VERSION "dbc-export 1 2025.20.8"

NS_ :

BS_:

BU_: ADSP APB APP APS APSB BB BMS CC CMP CMPD CP DAS DI DIF DIR DPB EPAS3P EPAS3S EPASTP EPASTS EPBL EPBR ESP EVSE FC GTW HCML HCMR HVP IBST ICR IDB LS OCS1P ODIN PARK PCS PLG PM PMF PMR PNCD PTC RADC RCM RCM2 RCM3 RCU SCCM SCM SCS SDCR TAS TCU TPMS TRCM UDS UI UIS UMC USM VC VCFRONT VCLEFT VCRIGHT VCSEC VEH

BO_ 809 APP_warningMatrix0: 8 APP
 SG_ APP_w001_DEPRECATED : 0|1@1+ (1,0) [0|1] "" Vector__XXX
 SG_ APP_w002_ldwDisabled : 1|1@1+ (1,0) [0|1] "" Vector__XXX
 SG_ APP_w003_isaDisabled : 2|1@1+ (1,0) [0|1] "" Vector__XXX
 SG_ APP_w004_accDisabled : 3|1@1+ (1,0) [0|1] "" Vector__XXX
 SG_ APP_w005_fcwCancelled : 4|1@1+ (1,0) [0|1] "" Vector__XXX
 SG_ APP_w006_aebCancelled : 5|1@1+ (1,0) [0|1] "" Vector__XXX
 SG_ APP_w007_ahlbDisabled : 6|1@1+ (1,0) [0|1] "" Vector__XXX
 SG_ APP_w008_parkDisabled : 7|1@1+ (1,0) [0|1] "" Vector__XXX
 SG_ APP_w009_aebFault : 8|1@1+ (1,0) [0|1] "" Vector__XXX
 SG_ APP_w010_radcCalibIssue : 9|1@1+ (1,0) [0|1] "" Vector__XXX
 SG_ APP_w011_scaEvent : 10|1@1+ (1,0) [0|1] "" Vector__XXX
 SG_ APP_w012_Cam_BootFailure : 11|1@1+ (1,0) [0|1] "" Vector__XXX
 SG_ APP_w013_Cam_Watchdog : 12|1@1+ (1,0) [0|1] "" Vector__XXX
 SG_ APP_w014_swAssert : 13|1@1+ (1,0) [0|1] "" Vector__XXX
 SG_ APP_w015_Camera_Failsafes : 14|1@1+ (1,0) [0|1] "" Vector__XXX
 SG_ APP_w016_aeb_e_event : 15|1@1+ (1,0) [0|1] "" Vector__XXX
 SG_ APP_w017_Cam_Msg_MIA : 16|1@1+ (1,0) [0|1] "" Vector__XXX
 SG_ APP_w018_ECU_Power_Issue : 17|1@1+ (1,0) [0|1] "" Vector__XXX
 SG_ APP_w019_ECU_Stack_Overflow : 18|1@1+ (1,0) [0|1] "" Vector__XXX
 SG_ APP_w020_ECU_checkstopError : 19|1@1+ (1,0) [0|1] "" Vector__XXX
 SG_ APP_w021_ECU_Temperature_Issue : 20|1@1+ (1,0) [0|1] "" Vector__XXX
 SG_ APP_w022_ECU_EEPROM_Failure : 21|1@1+ (1,0) [0|1] "" Vector__XXX
 SG_ APP_w023_ECU_Cam_Statemismatc : 22|1@1+ (1,0) [0|1] "" Vector__XXX
 SG_ APP_w024_ECU_Watchdog_Reset : 23|1@1+ (1,0) [0|1] "" Vector__XXX
 SG_ APP_w025_LC_Steering_Override : 24|1@1+ (1,0) [0|1] "" Vector__XXX
 SG_ APP_w026_ECU_timingIssue : 25|1@1+ (1,0) [0|1] "" Vector__XXX
 SG_ APP_w027_ECU_Reset_Fault : 26|1@1+ (1,0) [0|1] "" Vector__XXX
 SG_ APP_w028_spi_rx_error : 27|1@1+ (1,0) [0|1] "" Vector__XXX
 SG_ APP_w029_spi_tx_error : 28|1@1+ (1,0) [0|1] "" Vector__XXX
 SG_ APP_w030_Heater_Issue : 29|1@1+ (1,0) [0|1] "" Vector__XXX
 SG_ APP_w031_canRxError : 30|1@1+ (1,0) [0|1] "" Vector__XXX
 SG_ APP_w032_canTxError : 31|1@1+ (1,0) [0|1] "" Vector__XXX
 SG_ APP_w033_gtwMia : 32|1@1+ (1,0) [0|1] "" Vector__XXX
 SG_ APP_w034_sccmMia : 33|1@1+ (1,0) [0|1] "" Vector__XXX
 SG_ APP_w035_espMia : 34|1@1+ (1,0) [0|1] "" Vector__XXX
 SG_ APP_w036_bdyMia : 35|1@1+ (1,0) [0|1] "" Vector__XXX
 SG_ APP_w037_camTacIssue : 36|1@1+ (1,0) [0|1] "" Vector__XXX
 SG_ APP_w038_camFailure : 37|1@1+ (1,0) [0|1] "" Vector__XXX
 SG_ APP_w039_sdm_rcm_Mia : 38|1@1+ (1,0) [0|1] "" Vector__XXX
 SG_ APP_w040_autopilotAngleSaturated : 39|1@1+ (1,0) [0|1] "" Vector__XXX
 SG_ APP_w041_autopilotRateSaturated : 40|1@1+ (1,0) [0|1] "" Vector__XXX
 SG_ APP_w042_autopilotAborting : 41|1@1+ (1,0) [0|1] "" Vector__XXX
 SG_ APP_w043_camLongRunTime : 42|1@1+ (1,0) [0|1] "" Vector__XXX
 SG_ APP_w044_appMobileyeFailure : 43|1@1+ (1,0) [0|1] "" Vector__XXX
 SG_ APP_w045_radMia : 44|1@1+ (1,0) [0|1] "" Vector__XXX
 SG_ APP_w046_eepromRecordAbsent : 45|1@1+ (1,0) [0|1] "" Vector__XXX
 SG_ APP_w047_edrEvent : 46|1@1+ (1,0) [0|1] "" Vector__XXX
 SG_ APP_w048_APP_Features_Disabled : 47|1@1+ (1,0) [0|1] "" Vector__XXX
 SG_ APP_w049_eyeqVersionMismatch : 48|1@1+ (1,0) [0|1] "" Vector__XXX
 SG_ APP_w050_aeb_event : 49|1@1+ (1,0) [0|1] "" Vector__XXX
 SG_ APP_w051_radcEcuIssue : 50|1@1+ (1,0) [0|1] "" Vector__XXX
 SG_ APP_w052_radcSensorIssue : 51|1@1+ (1,0) [0|1] "" Vector__XXX
 SG_ APP_w053_radcCommIssue : 52|1@1+ (1,0) [0|1] "" Vector__XXX
 SG_ APP_w054_camAutofix : 53|1@1+ (1,0) [0|1] "" Vector__XXX
 SG_ APP_w055_radcVersionMismatch : 54|1@1+ (1,0) [0|1] "" Vector__XXX
 SG_ APP_w056_diMia : 55|1@1+ (1,0) [0|1] "" Vector__XXX
 SG_ APP_w057_mcuMia : 56|1@1+ (1,0) [0|1] "" Vector__XXX
 SG_ APP_w058_epbMia : 57|1@1+ (1,0) [0|1] "" Vector__XXX
 SG_ APP_w059_parkMia : 58|1@1+ (1,0) [0|1] "" Vector__XXX
 SG_ APP_w060_fcw_event : 59|1@1+ (1,0) [0|1] "" Vector__XXX
 SG_ APP_w061_airSuspensionMia : 60|1@1+ (1,0) [0|1] "" Vector__XXX
 SG_ APP_w062_radcAlignment : 61|1@1+ (1,0) [0|1] "" Vector__XXX
 SG_ APP_w063_parkVersionMismatch : 62|1@1+ (1,0) [0|1] "" Vector__XXX
 SG_ APP_w064_epasMia : 63|1@1+ (1,0) [0|1] "" Vector__XXX

BO_ 873 APP_warningMatrix1: 8 APP
 SG_ APP_w065_deserializerOvercurrent : 0|1@1+ (1,0) [0|1] "" Vector__XXX
 SG_ APP_w066_deserializerLockLost : 1|1@1+ (1,0) [0|1] "" Vector__XXX
 SG_ APP_w067_steeringAlignment : 2|1@1+ (1,0) [0|1] "" Vector__XXX
 SG_ APP_w068_vlInconsistency : 3|1@1+ (1,0) [0|1] "" Vector__XXX
 SG_ APP_w069_apcSpaceMasked : 4|1@1+ (1,0) [0|1] "" Vector__XXX
 SG_ APP_w070_apcIncompleteCal : 5|1@1+ (1,0) [0|1] "" Vector__XXX
 SG_ APP_w071_selfparkStarted : 6|1@1+ (1,0) [0|1] "" Vector__XXX
 SG_ APP_w072_selfparkComplete : 7|1@1+ (1,0) [0|1] "" Vector__XXX
 SG_ APP_w073_issueEscalatedLDW : 8|1@1+ (1,0) [0|1] "" Vector__XXX
 SG_ APP_w074_inPathStationaryObst : 9|1@1+ (1,0) [0|1] "" Vector__XXX
 SG_ APP_w075_scMia : 10|1@1+ (1,0) [0|1] "" Vector__XXX
 SG_ APP_w076_mobilEyeSetC : 11|1@1+ (1,0) [0|1] "" Vector__XXX
 SG_ APP_w077_pmmActive : 12|1@1+ (1,0) [0|1] "" Vector__XXX
 SG_ APP_w078_pmmActive2 : 13|1@1+ (1,0) [0|1] "" Vector__XXX
 SG_ APP_w079_edrAvailable : 14|1@1+ (1,0) [0|1] "" Vector__XXX
 SG_ APP_w080_accFailedActivation : 15|1@1+ (1,0) [0|1] "" Vector__XXX
 SG_ APP_w081_pmmActiveBraking : 16|1@1+ (1,0) [0|1] "" Vector__XXX
 SG_ APP_w082_inPathFSviolation : 17|1@1+ (1,0) [0|1] "" Vector__XXX
 SG_ APP_w083_inPathRADObject : 18|1@1+ (1,0) [0|1] "" Vector__XXX
 SG_ APP_w084_pmmIPSO : 19|1@1+ (1,0) [0|1] "" Vector__XXX
 SG_ APP_w085_pmmSteering : 20|1@1+ (1,0) [0|1] "" Vector__XXX
 SG_ APP_w086_robCollision : 21|1@1+ (1,0) [0|1] "" Vector__XXX
 SG_ APP_w087_DEPRECATED : 22|1@1+ (1,0) [0|1] "" Vector__XXX
 SG_ APP_w088_DEPRECATED : 23|1@1+ (1,0) [0|1] "" Vector__XXX
 SG_ APP_w089_DEPRECATED : 24|1@1+ (1,0) [0|1] "" Vector__XXX
 SG_ APP_w090_DEPRECATED : 25|1@1+ (1,0) [0|1] "" Vector__XXX
 SG_ APP_w091_DEPRECATED : 26|1@1+ (1,0) [0|1] "" Vector__XXX
 SG_ APP_w092_DEPRECATED : 27|1@1+ (1,0) [0|1] "" Vector__XXX
 SG_ APP_w093_DEPRECATED : 28|1@1+ (1,0) [0|1] "" Vector__XXX
 SG_ APP_w094_DEPRECATED : 29|1@1+ (1,0) [0|1] "" Vector__XXX
 SG_ APP_w095_DEPRECATED : 30|1@1+ (1,0) [0|1] "" Vector__XXX
 SG_ APP_w096_DEPRECATED : 31|1@1+ (1,0) [0|1] "" Vector__XXX
 SG_ APP_w097_DEPRECATED : 32|1@1+ (1,0) [0|1] "" Vector__XXX
 SG_ APP_w098_DEPRECATED : 33|1@1+ (1,0) [0|1] "" Vector__XXX
 SG_ APP_w099_DEPRECATED : 34|1@1+ (1,0) [0|1] "" Vector__XXX
 SG_ APP_w100_DEPRECATED : 35|1@1+ (1,0) [0|1] "" Vector__XXX
 SG_ APP_w101_DEPRECATED : 36|1@1+ (1,0) [0|1] "" Vector__XXX
 SG_ APP_w102_DEPRECATED : 37|1@1+ (1,0) [0|1] "" Vector__XXX
 SG_ APP_w103_robExperimentalAEB : 38|1@1+ (1,0) [0|1] "" Vector__XXX
 SG_ APP_w104_DEPRECATED : 39|1@1+ (1,0) [0|1] "" Vector__XXX
 SG_ APP_w105_DEPRECATED : 40|1@1+ (1,0) [0|1] "" Vector__XXX
 SG_ APP_w106_torsionBarOffset : 41|1@1+ (1,0) [0|1] "" Vector__XXX

BO_ 1065 APP_warningMatrix2: 8 APP
 SG_ APP_w129_mainCamExtNotCal : 0|1@1+ (1,0) [0|1] "" Vector__XXX
 SG_ APP_w130_narrowCamExtNotCal : 1|1@1+ (1,0) [0|1] "" Vector__XXX
 SG_ APP_w131_mainCamCalSaved : 2|1@1+ (1,0) [0|1] "" Vector__XXX
 SG_ APP_w132_narrowCamCalSaved : 3|1@1+ (1,0) [0|1] "" Vector__XXX
 SG_ APP_w133_mainCamInitFault : 4|1@1+ (1,0) [0|1] "" Vector__XXX
 SG_ APP_w134_narrowCamInitFault : 5|1@1+ (1,0) [0|1] "" Vector__XXX
 SG_ APP_w135_fisheyeCamInitFault : 6|1@1+ (1,0) [0|1] "" Vector__XXX
 SG_ APP_w136_lPillarCamInitFault : 7|1@1+ (1,0) [0|1] "" Vector__XXX
 SG_ APP_w137_rPillarCamInitFault : 8|1@1+ (1,0) [0|1] "" Vector__XXX
 SG_ APP_w138_lRepeatCamInitFault : 9|1@1+ (1,0) [0|1] "" Vector__XXX
 SG_ APP_w139_rRepeatCamInitFault : 10|1@1+ (1,0) [0|1] "" Vector__XXX
 SG_ APP_w140_backupCamInitFault : 11|1@1+ (1,0) [0|1] "" Vector__XXX
 SG_ APP_w141_ECU_Thermal_Issue : 12|1@1+ (1,0) [0|1] "" Vector__XXX
 SG_ APP_w142_fwdCamPitchProblem : 13|1@1+ (1,0) [0|1] "" Vector__XXX
 SG_ APP_w143_IDF_event : 14|1@1+ (1,0) [0|1] "" Vector__XXX
 SG_ APP_w144_fanctrldError : 15|1@1+ (1,0) [0|1] "" Vector__XXX
 SG_ APP_w145_camSelfCalIssue : 16|1@1+ (1,0) [0|1] "" Vector__XXX
 SG_ APP_w146_telemetryProblem : 17|1@1+ (1,0) [0|1] "" Vector__XXX
 SG_ APP_w147_selfieCamInitFault : 18|1@1+ (1,0) [0|1] "" Vector__XXX
 SG_ APP_w148_overlayActive : 19|1@1+ (1,0) [0|1] "" Vector__XXX
 SG_ APP_w149_diskFull : 20|1@1+ (1,0) [0|1] "" Vector__XXX
 SG_ APP_w150_diMiaPartyBus : 21|1@1+ (1,0) [0|1] "" Vector__XXX
 SG_ APP_w151_epasMiaPartyBus : 22|1@1+ (1,0) [0|1] "" Vector__XXX
 SG_ APP_w152_espMiaPartyBus : 23|1@1+ (1,0) [0|1] "" Vector__XXX
 SG_ APP_w153_rcmMiaPartyBus : 24|1@1+ (1,0) [0|1] "" Vector__XXX
 SG_ APP_w154_vcleftMiaPartyBus : 25|1@1+ (1,0) [0|1] "" Vector__XXX
 SG_ APP_w155_vcrightMiaPartyBus : 26|1@1+ (1,0) [0|1] "" Vector__XXX
 SG_ APP_w156_epblMiaVehBus : 27|1@1+ (1,0) [0|1] "" Vector__XXX
 SG_ APP_w157_sccmMiaVehBus : 28|1@1+ (1,0) [0|1] "" Vector__XXX
 SG_ APP_w158_vcfrontMiaVehBus : 29|1@1+ (1,0) [0|1] "" Vector__XXX
 SG_ APP_w159_vcleftMiaVehBus : 30|1@1+ (1,0) [0|1] "" Vector__XXX
 SG_ APP_w160_vcrightMiaVehBus : 31|1@1+ (1,0) [0|1] "" Vector__XXX
 SG_ APP_w161_backupCameraUnavailable : 32|1@1+ (1,0) [0|1] "" Vector__XXX
 SG_ APP_w162_mainCameraTypeError : 33|1@1+ (1,0) [0|1] "" Vector__XXX
 SG_ APP_w163_narrowCameraTypeError : 34|1@1+ (1,0) [0|1] "" Vector__XXX
 SG_ APP_w164_fisheyeCameraTypeError : 35|1@1+ (1,0) [0|1] "" Vector__XXX
 SG_ APP_w165_lPillarCameraTypeError : 36|1@1+ (1,0) [0|1] "" Vector__XXX
 SG_ APP_w166_rPillarCameraTypeError : 37|1@1+ (1,0) [0|1] "" Vector__XXX
 SG_ APP_w167_lRepeatCameraTypeError : 38|1@1+ (1,0) [0|1] "" Vector__XXX
 SG_ APP_w168_rRepeatCameraTypeError : 39|1@1+ (1,0) [0|1] "" Vector__XXX
 SG_ APP_w169_backupCameraTypeError : 40|1@1+ (1,0) [0|1] "" Vector__XXX
 SG_ APP_w170_selfieCameraTypeError : 41|1@1+ (1,0) [0|1] "" Vector__XXX
 SG_ APP_w171_appHighCoolantFlowReq : 42|1@1+ (1,0) [0|1] "" Vector__XXX
 SG_ APP_w172_fisheyeCamExtNotCal : 43|1@1+ (1,0) [0|1] "" Vector__XXX
 SG_ APP_w173_lPillarCamExtNotCal : 44|1@1+ (1,0) [0|1] "" Vector__XXX
 SG_ APP_w174_rPillarCamExtNotCal : 45|1@1+ (1,0) [0|1] "" Vector__XXX
 SG_ APP_w175_lRepeatCamExtNotCal : 46|1@1+ (1,0) [0|1] "" Vector__XXX
 SG_ APP_w176_rRepeatCamExtNotCal : 47|1@1+ (1,0) [0|1] "" Vector__XXX
 SG_ APP_w177_fisheyeCamCalSaved : 48|1@1+ (1,0) [0|1] "" Vector__XXX
 SG_ APP_w178_lPillarCamCalSaved : 49|1@1+ (1,0) [0|1] "" Vector__XXX
 SG_ APP_w179_rPillarCamCalSaved : 50|1@1+ (1,0) [0|1] "" Vector__XXX
 SG_ APP_w180_lRepeatCamCalSaved : 51|1@1+ (1,0) [0|1] "" Vector__XXX
 SG_ APP_w181_rRepeatCamCalSaved : 52|1@1+ (1,0) [0|1] "" Vector__XXX
 SG_ APP_w182_mainCameraStreamExit : 53|1@1+ (1,0) [0|1] "" Vector__XXX
 SG_ APP_w183_narrowCameraStreamExit : 54|1@1+ (1,0) [0|1] "" Vector__XXX
 SG_ APP_w184_fisheyeCameraStreamExit : 55|1@1+ (1,0) [0|1] "" Vector__XXX
 SG_ APP_w185_lPillarCameraStreamExit : 56|1@1+ (1,0) [0|1] "" Vector__XXX
 SG_ APP_w186_rPillarCameraStreamExit : 57|1@1+ (1,0) [0|1] "" Vector__XXX
 SG_ APP_w187_lRepeatCameraStreamExit : 58|1@1+ (1,0) [0|1] "" Vector__XXX
 SG_ APP_w188_rRepeatCameraStreamExit : 59|1@1+ (1,0) [0|1] "" Vector__XXX
 SG_ APP_w189_backupCameraStreamExit : 60|1@1+ (1,0) [0|1] "" Vector__XXX
 SG_ APP_w190_selfieCameraStreamExit : 61|1@1+ (1,0) [0|1] "" Vector__XXX
 SG_ APP_w191_autopilotAborting : 62|1@1+ (1,0) [0|1] "" Vector__XXX
 SG_ APP_w192_emergencySpeakerFail : 63|1@1+ (1,0) [0|1] "" Vector__XXX

BO_ 1081 APP_warningMatrix3: 8 APP
 SG_ APP_w193_camWindshieldUnclean : 0|1@1+ (1,0) [0|1] "" Vector__XXX
 SG_ APP_w194_accDriverResumeRqrd : 1|1@1+ (1,0) [0|1] "" Vector__XXX
 SG_ APP_w195_scwUnavailable : 2|1@1+ (1,0) [0|1] "" Vector__XXX
 SG_ APP_w196_stopSignWarning : 3|1@1+ (1,0) [0|1] "" Vector__XXX
 SG_ APP_w197_redLightWarning : 4|1@1+ (1,0) [0|1] "" Vector__XXX
 SG_ APP_w198_tsrUnavailable : 5|1@1+ (1,0) [0|1] "" Vector__XXX
 SG_ APP_w199_apcAbort : 6|1@1+ (1,0) [0|1] "" Vector__XXX
 SG_ APP_w200_lcSlowdown : 7|1@1+ (1,0) [0|1] "" Vector__XXX
 SG_ APP_w201_lcAborting : 8|1@1+ (1,0) [0|1] "" Vector__XXX
 SG_ APP_w202_scwNoisyEnvironment : 9|1@1+ (1,0) [0|1] "" Vector__XXX
 SG_ APP_w203_apcActivation : 10|1@1+ (1,0) [0|1] "" Vector__XXX
 SG_ APP_w204_apcFinalFront : 11|1@1+ (1,0) [0|1] "" Vector__XXX
 SG_ APP_w205_apcFinalRear : 12|1@1+ (1,0) [0|1] "" Vector__XXX
 SG_ APP_w206_autosteerNotEnabled : 13|1@1+ (1,0) [0|1] "" Vector__XXX
 SG_ APP_w207_autosteerUnavailable : 14|1@1+ (1,0) [0|1] "" Vector__XXX
 SG_ APP_w208_rackDetected : 15|1@1+ (1,0) [0|1] "" Vector__XXX
 SG_ APP_w209_autoSummonRequest : 16|1@1+ (1,0) [0|1] "" Vector__XXX
 SG_ APP_w210_camObstrcted : 17|1@1+ (1,0) [0|1] "" Vector__XXX
 SG_ APP_w211_accNoSeatBelt : 18|1@1+ (1,0) [0|1] "" Vector__XXX
 SG_ APP_w212_lcUnavailableStrikeOut : 19|1@1+ (1,0) [0|1] "" Vector__XXX
 SG_ APP_w213_autosteerStruckOut : 20|1@1+ (1,0) [0|1] "" Vector__XXX
 SG_ APP_w214_driverNotIntracting : 21|1@1+ (1,0) [0|1] "" Vector__XXX
 SG_ APP_w215_contDriverNotIntracting : 22|1@1+ (1,0) [0|1] "" Vector__XXX
 SG_ APP_w216_driverOverriding : 23|1@1+ (1,0) [0|1] "" Vector__XXX
 SG_ APP_w217_lcUnavailableSpeeding : 24|1@1+ (1,0) [0|1] "" Vector__XXX
 SG_ APP_w218_lcSpeedExceededLimit : 25|1@1+ (1,0) [0|1] "" Vector__XXX
 SG_ APP_w219_lcTempUnavailableSpeed : 26|1@1+ (1,0) [0|1] "" Vector__XXX
 SG_ APP_w220_lcTempUnavailableRoad : 27|1@1+ (1,0) [0|1] "" Vector__XXX
 SG_ APP_w221_accRadarBlind : 28|1@1+ (1,0) [0|1] "" Vector__XXX
 SG_ APP_w222_accCameraBlind : 29|1@1+ (1,0) [0|1] "" Vector__XXX
 SG_ APP_w223_accObjectInPath : 30|1@1+ (1,0) [0|1] "" Vector__XXX
 SG_ APP_w224_accCameraCalibration : 31|1@1+ (1,0) [0|1] "" Vector__XXX
 SG_ APP_w225_lcDegradedVisSpeedLmt : 32|1@1+ (1,0) [0|1] "" Vector__XXX
 SG_ APP_w226_lcCamCalNeededSpeedLmt : 33|1@1+ (1,0) [0|1] "" Vector__XXX
 SG_ APP_w227_virtualWallBlocked : 34|1@1+ (1,0) [0|1] "" Vector__XXX
 SG_ APP_w228_DEPRECATED : 35|1@1+ (1,0) [0|1] "" Vector__XXX
 SG_ APP_w229_alcUltrasoundDamaged : 36|1@1+ (1,0) [0|1] "" Vector__XXX
 SG_ APP_w230_alcUltrasoundBlocked : 37|1@1+ (1,0) [0|1] "" Vector__XXX
 SG_ APP_w231_idfEvent : 38|1@1+ (1,0) [0|1] "" Vector__XXX
 SG_ APP_w232_laneChangeRequested : 39|1@1+ (1,0) [0|1] "" Vector__XXX
 SG_ APP_w234_activeSafetyTelemetry : 41|1@1+ (1,0) [0|1] "" Vector__XXX

BO_ 1097 APP_warningMatrix4: 8 APP
 SG_ APP_w257_brakeJerkEvent : 0|1@1+ (1,0) [0|1] "" Vector__XXX
 SG_ APP_w258_aebEvent : 1|1@1+ (1,0) [0|1] "" Vector__XXX
 SG_ APP_w259_aebOverrideEvent : 2|1@1+ (1,0) [0|1] "" Vector__XXX
 SG_ APP_w260_collisionWarningEvent : 3|1@1+ (1,0) [0|1] "" Vector__XXX
 SG_ APP_w261_pcieHardwareErrors : 4|1@1+ (1,0) [0|1] "" Vector__XXX
 SG_ APP_w262_apeCalibMode : 5|1@1+ (1,0) [0|1] "" Vector__XXX
 SG_ APP_w263_lssAbort : 6|1@1+ (1,0) [0|1] "" Vector__XXX
 SG_ APP_w264_lssFault : 7|1@1+ (1,0) [0|1] "" Vector__XXX
 SG_ APP_w265_drvOnNavUnavailable : 8|1@1+ (1,0) [0|1] "" Vector__XXX
 SG_ APP_w266_visionScheduleFallback : 9|1@1+ (1,0) [0|1] "" Vector__XXX
 SG_ APP_w267_benchtopEcu : 10|1@1+ (1,0) [0|1] "" Vector__XXX
 SG_ APP_w268_backupCamExtNotCal : 11|1@1+ (1,0) [0|1] "" Vector__XXX
 SG_ APP_w269_autopilotLimited : 12|1@1+ (1,0) [0|1] "" Vector__XXX
 SG_ APP_w270_blindspotRestricted : 13|1@1+ (1,0) [0|1] "" Vector__XXX
 SG_ APP_w271_laneChangeAborted : 14|1@1+ (1,0) [0|1] "" Vector__XXX
 SG_ APP_w272_laneChangeUnavailable : 15|1@1+ (1,0) [0|1] "" Vector__XXX
 SG_ APP_w273_lssEvent : 16|1@1+ (1,0) [0|1] "" Vector__XXX
 SG_ APP_w274_mainCameraStreamErr : 17|1@1+ (1,0) [0|1] "" Vector__XXX
 SG_ APP_w275_narrowCameraStreamErr : 18|1@1+ (1,0) [0|1] "" Vector__XXX
 SG_ APP_w276_fisheyeCameraStreamErr : 19|1@1+ (1,0) [0|1] "" Vector__XXX
 SG_ APP_w277_lPillarCameraStreamErr : 20|1@1+ (1,0) [0|1] "" Vector__XXX
 SG_ APP_w278_rPillarCameraStreamErr : 21|1@1+ (1,0) [0|1] "" Vector__XXX
 SG_ APP_w279_lRepeatCameraStreamErr : 22|1@1+ (1,0) [0|1] "" Vector__XXX
 SG_ APP_w280_rRepeatCameraStreamErr : 23|1@1+ (1,0) [0|1] "" Vector__XXX
 SG_ APP_w281_backupCameraStreamErr : 24|1@1+ (1,0) [0|1] "" Vector__XXX
 SG_ APP_w282_selfieCameraStreamErr : 25|1@1+ (1,0) [0|1] "" Vector__XXX
 SG_ APP_w283_enhancedSummonAbort : 26|1@1+ (1,0) [0|1] "" Vector__XXX
 SG_ APP_w284_gpsAntennaDisconnected : 27|1@1+ (1,0) [0|1] "" Vector__XXX
 SG_ APP_w285_gpsFaultReset : 28|1@1+ (1,0) [0|1] "" Vector__XXX
 SG_ APP_w286_gpsComIssue : 29|1@1+ (1,0) [0|1] "" Vector__XXX
 SG_ APP_w287_gpsFusionStatus : 30|1@1+ (1,0) [0|1] "" Vector__XXX
 SG_ APP_w288_trafficLightWarning : 31|1@1+ (1,0) [0|1] "" Vector__XXX
 SG_ APP_w289_dramCorrEccErrors : 32|1@1+ (1,0) [0|1] "" Vector__XXX
 SG_ APP_w290_dramUncorrEccErrors : 33|1@1+ (1,0) [0|1] "" Vector__XXX
 SG_ APP_w291_stopSignWarning : 34|1@1+ (1,0) [0|1] "" Vector__XXX
 SG_ APP_w293_mainCameraSyncFailed : 36|1@1+ (1,0) [0|1] "" Vector__XXX
 SG_ APP_w294_narrowCameraSyncFailed : 37|1@1+ (1,0) [0|1] "" Vector__XXX
 SG_ APP_w295_fisheyeCameraSyncFailed : 38|1@1+ (1,0) [0|1] "" Vector__XXX
 SG_ APP_w296_lPillarCameraSyncFailed : 39|1@1+ (1,0) [0|1] "" Vector__XXX
 SG_ APP_w297_rPillarCameraSyncFailed : 40|1@1+ (1,0) [0|1] "" Vector__XXX
 SG_ APP_w298_lRepeatCameraSyncFailed : 41|1@1+ (1,0) [0|1] "" Vector__XXX
 SG_ APP_w299_rRepeatCameraSyncFailed : 42|1@1+ (1,0) [0|1] "" Vector__XXX
 SG_ APP_w300_backupCameraSyncFailed : 43|1@1+ (1,0) [0|1] "" Vector__XXX
 SG_ APP_w301_selfieCameraSyncFailed : 44|1@1+ (1,0) [0|1] "" Vector__XXX
 SG_ APP_w302_vcfrontMiaPartyBus : 45|1@1+ (1,0) [0|1] "" Vector__XXX
 SG_ APP_w303_imuIrational : 46|1@1+ (1,0) [0|1] "" Vector__XXX
 SG_ APP_w304_lssCamBlockedStatus : 47|1@1+ (1,0) [0|1] "" Vector__XXX
 SG_ APP_w305_lssCamStreamExit : 48|1@1+ (1,0) [0|1] "" Vector__XXX
 SG_ APP_w306_lssUltrasonicsBlocked : 49|1@1+ (1,0) [0|1] "" Vector__XXX
 SG_ APP_w307_lssTurnSignalFault : 50|1@1+ (1,0) [0|1] "" Vector__XXX
 SG_ APP_w308_iboosterMia : 51|1@1+ (1,0) [0|1] "" Vector__XXX
 SG_ APP_w309_selfieDisabledOnCar : 52|1@1+ (1,0) [0|1] "" Vector__XXX
 SG_ APP_w310_eth0FrameErrors : 53|1@1+ (1,0) [0|1] "" Vector__XXX
 SG_ APP_w311_eth1FrameErrors : 54|1@1+ (1,0) [0|1] "" Vector__XXX
 SG_ APP_w312_mainCamTypeMismatch : 55|1@1+ (1,0) [0|1] "" Vector__XXX
 SG_ APP_w313_narrowCamTypeMismatch : 56|1@1+ (1,0) [0|1] "" Vector__XXX
 SG_ APP_w314_fisheyeCamTypeMismatch : 57|1@1+ (1,0) [0|1] "" Vector__XXX
 SG_ APP_w315_lPillarCamTypeMismatch : 58|1@1+ (1,0) [0|1] "" Vector__XXX
 SG_ APP_w316_rPillarCamTypeMismatch : 59|1@1+ (1,0) [0|1] "" Vector__XXX
 SG_ APP_w317_lRepeatCamTypeMismatch : 60|1@1+ (1,0) [0|1] "" Vector__XXX
 SG_ APP_w318_rRepeatCamTypeMismatch : 61|1@1+ (1,0) [0|1] "" Vector__XXX
 SG_ APP_w319_backupCamTypeMismatch : 62|1@1+ (1,0) [0|1] "" Vector__XXX
 SG_ APP_w320_selfieCamTypeMismatch : 63|1@1+ (1,0) [0|1] "" Vector__XXX

BO_ 1145 APP_warningMatrix5: 8 APP
 SG_ APP_w321_bmsMia : 0|1@1+ (1,0) [0|1] "" Vector__XXX
 SG_ APP_w322_autoWiperWash : 1|1@1+ (1,0) [0|1] "" Vector__XXX
 SG_ APP_w323_drivableSpaceFCW : 2|1@1+ (1,0) [0|1] "" Vector__XXX
 SG_ APP_w324_adspMia : 3|1@1+ (1,0) [0|1] "" Vector__XXX
 SG_ APP_w325_watchdogReset : 4|1@1+ (1,0) [0|1] "" Vector__XXX
 SG_ APP_w326_kernelPanic : 5|1@1+ (1,0) [0|1] "" Vector__XXX
 SG_ APP_w327_vehicleConfigMismatch : 6|1@1+ (1,0) [0|1] "" Vector__XXX
 SG_ APP_w328_autoparkDegraded : 7|1@1+ (1,0) [0|1] "" Vector__XXX
 SG_ APP_w329_evasiveManeuver : 8|1@1+ (1,0) [0|1] "" Vector__XXX
 SG_ APP_w330_cabinCameraFault : 9|1@1+ (1,0) [0|1] "" Vector__XXX
 SG_ APP_w331_fsdDegradedUnavailable : 10|1@1+ (1,0) [0|1] "" Vector__XXX
 SG_ APP_w332_cameraPositionsSwapped : 11|1@1+ (1,0) [0|1] "" Vector__XXX
 SG_ APP_w333_fsdUnavailableLocation : 12|1@1+ (1,0) [0|1] "" Vector__XXX
 SG_ APP_w334_frontCameraOccluded : 13|1@1+ (1,0) [0|1] "" Vector__XXX
 SG_ APP_w335_tradfcRfSensorError : 14|1@1+ (1,0) [0|1] "" Vector__XXX
 SG_ APP_w336_tradfcLfPmicError : 15|1@1+ (1,0) [0|1] "" Vector__XXX
 SG_ APP_w337_tradfcRfPmicError : 16|1@1+ (1,0) [0|1] "" Vector__XXX
 SG_ APP_w338_tradfcLfTempError : 17|1@1+ (1,0) [0|1] "" Vector__XXX
 SG_ APP_w339_tradfcRfTempError : 18|1@1+ (1,0) [0|1] "" Vector__XXX
 SG_ APP_w340_tradfcCsiError : 19|1@1+ (1,0) [0|1] "" Vector__XXX
 SG_ APP_w341_tradfcCalibError : 20|1@1+ (1,0) [0|1] "" Vector__XXX
 SG_ APP_w342_tradfcDspHwError : 21|1@1+ (1,0) [0|1] "" Vector__XXX
 SG_ APP_w343_tradfcDspSwError : 22|1@1+ (1,0) [0|1] "" Vector__XXX
 SG_ APP_w344_tradfcDspAlgoTimeout : 23|1@1+ (1,0) [0|1] "" Vector__XXX
 SG_ APP_w345_tradfcPerfDegraded : 24|1@1+ (1,0) [0|1] "" Vector__XXX
 SG_ APP_w346_gpsSwEvent : 25|1@1+ (1,0) [0|1] "" Vector__XXX
 SG_ APP_w347_vcbattMiaVehBus : 26|1@1+ (1,0) [0|1] "" Vector__XXX
 SG_ APP_w348_cameraSwUpdateRequired : 27|1@1+ (1,0) [0|1] "" Vector__XXX
 SG_ APP_w349_cameraPersistentlyFault : 28|1@1+ (1,0) [0|1] "" Vector__XXX
 SG_ APP_w350_tradfcSensorMisaligned : 29|1@1+ (1,0) [0|1] "" Vector__XXX
 SG_ APP_w351_csiDevice0Down : 30|1@1+ (1,0) [0|1] "" Vector__XXX
 SG_ APP_w352_csiDevice1Down : 31|1@1+ (1,0) [0|1] "" Vector__XXX
 SG_ APP_w353_csiDevice2Down : 32|1@1+ (1,0) [0|1] "" Vector__XXX
 SG_ APP_w354_tradfcMia : 33|1@1+ (1,0) [0|1] "" Vector__XXX
 SG_ APP_w355_camQuadPowerFault : 34|1@1+ (1,0) [0|1] "" Vector__XXX
 SG_ APP_w356_driverOverriding : 35|1@1+ (1,0) [0|1] "" Vector__XXX
 SG_ APP_w357_ddawSystemFault : 36|1@1+ (1,0) [0|1] "" Vector__XXX
 SG_ APP_w358_isaSystemFault : 37|1@1+ (1,0) [0|1] "" Vector__XXX
 SG_ APP_w359_aebDegraded : 38|1@1+ (1,0) [0|1] "" Vector__XXX
 SG_ APP_w360_ApImuNoiseDetected : 39|1@1+ (1,0) [0|1] "" Vector__XXX
 SG_ APP_w361_cabinCameraLEDFault : 40|1@1+ (1,0) [0|1] "" Vector__XXX
 SG_ APP_w362_fasciaCamInitFault : 41|1@1+ (1,0) [0|1] "" Vector__XXX
 SG_ APP_w363_fasciaCameraStreamExit : 42|1@1+ (1,0) [0|1] "" Vector__XXX
 SG_ APP_w364_fasciaCameraTypeError : 43|1@1+ (1,0) [0|1] "" Vector__XXX
 SG_ APP_w365_fasciaCamExtNotCal : 44|1@1+ (1,0) [0|1] "" Vector__XXX
 SG_ APP_w366_fasciaCameraSyncFailed : 45|1@1+ (1,0) [0|1] "" Vector__XXX
 SG_ APP_w367_fasciaCamCalSaved : 46|1@1+ (1,0) [0|1] "" Vector__XXX
 SG_ APP_w368_fasciaCamTypeMismatch : 47|1@1+ (1,0) [0|1] "" Vector__XXX
 SG_ APP_w369_cruiseWithSingleClick : 48|1@1+ (1,0) [0|1] "" Vector__XXX
 SG_ APP_w370_accApUnavUserSettings : 49|1@1+ (1,0) [0|1] "" Vector__XXX
 SG_ APP_w371_networkLoadingIssue : 50|1@1+ (1,0) [0|1] "" Vector__XXX
 SG_ APP_w372_cabinCameraBlocked : 51|1@1+ (1,0) [0|1] "" Vector__XXX
 SG_ APP_w373_gnssUartError : 52|1@1+ (1,0) [0|1] "" Vector__XXX
 SG_ APP_w374_gnssUartDataMia : 53|1@1+ (1,0) [0|1] "" Vector__XXX
 SG_ APP_w375_gnssPpsMia : 54|1@1+ (1,0) [0|1] "" Vector__XXX
 SG_ APP_w376_wheeltickCountMia : 55|1@1+ (1,0) [0|1] "" Vector__XXX
 SG_ APP_w377_apImuMia : 56|1@1+ (1,0) [0|1] "" Vector__XXX
 SG_ APP_w378_ubloxImuMia : 57|1@1+ (1,0) [0|1] "" Vector__XXX
 SG_ APP_w379_positioningEngineMia : 58|1@1+ (1,0) [0|1] "" Vector__XXX
 SG_ APP_w380_gnssPpsTimestampIssue : 59|1@1+ (1,0) [0|1] "" Vector__XXX
 SG_ APP_w381_apImuTimestampIssue : 60|1@1+ (1,0) [0|1] "" Vector__XXX
 SG_ APP_w382_ubloxImuTimestampIssue : 61|1@1+ (1,0) [0|1] "" Vector__XXX
 SG_ APP_w383_manyApRebootsWhileInP : 62|1@1+ (1,0) [0|1] "" Vector__XXX
 SG_ APP_w384_posEngineInitInMotion : 63|1@1+ (1,0) [0|1] "" Vector__XXX

BO_ 1149 APP_warningMatrix6: 8 APP
 SG_ APP_w385_posEngineUnhealthy : 0|1@1+ (1,0) [0|1] "" Vector__XXX
 SG_ APP_w386_radarOnlyBrakingEvent : 1|1@1+ (1,0) [0|1] "" Vector__XXX
 SG_ APP_w387_radarBlockageDetected : 2|1@1+ (1,0) [0|1] "" Vector__XXX
 SG_ APP_w388_windshieldCameraHeaterF : 3|1@1+ (1,0) [0|1] "" Vector__XXX
 SG_ APP_w389_camFovResidueDetected : 4|1@1+ (1,0) [0|1] "" Vector__XXX
 SG_ APP_w390_cabinCamVisDegraded : 5|1@1+ (1,0) [0|1] "" Vector__XXX
 SG_ APP_w391_cabinCameraBlockedonAP : 6|1@1+ (1,0) [0|1] "" Vector__XXX
 SG_ APP_w392_fsdSuspended : 7|1@1+ (1,0) [0|1] "" Vector__XXX
 SG_ APP_w393_attnMntrUnavailable : 8|1@1+ (1,0) [0|1] "" Vector__XXX
 SG_ APP_w394_apImuGrossErrors : 9|1@1+ (1,0) [0|1] "" Vector__XXX
 SG_ APP_w395_cabinCameraLEDFaultSvc : 10|1@1+ (1,0) [0|1] "" Vector__XXX
 SG_ APP_w396_severeResidueDetected : 11|1@1+ (1,0) [0|1] "" Vector__XXX
 SG_ APP_w397_apFeatDisabledPermanent : 12|1@1+ (1,0) [0|1] "" Vector__XXX
 SG_ APP_w398_imuOutputUnhealthy : 13|1@1+ (1,0) [0|1] "" Vector__XXX
 SG_ APP_w399_brakeboosterMia : 14|1@1+ (1,0) [0|1] "" Vector__XXX
 SG_ APP_w400_selfieCameraFanFault : 15|1@1+ (1,0) [0|1] "" Vector__XXX
 SG_ APP_w401_leftPillarCameraHeaterF : 16|1@1+ (1,0) [0|1] "" Vector__XXX
 SG_ APP_w402_rightPillarCameraHeater : 17|1@1+ (1,0) [0|1] "" Vector__XXX

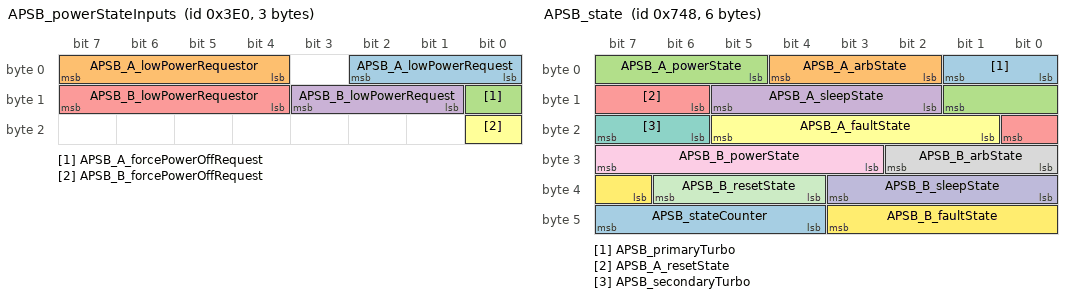
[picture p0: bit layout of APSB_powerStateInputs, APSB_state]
BO_ 992 APSB_powerStateInputs: 3 APSB
 SG_ APSB_A_lowPowerRequest : 0|3@1+ (1,0) [0|7] "" Vector__XXX
 SG_ APSB_A_lowPowerRequestor : 4|4@1+ (1,0) [0|15] "" Vector__XXX
 SG_ APSB_A_forcePowerOffRequest : 8|1@1+ (1,0) [0|1] "" Vector__XXX
 SG_ APSB_B_lowPowerRequest : 9|3@1+ (1,0) [0|7] "" Vector__XXX
 SG_ APSB_B_lowPowerRequestor : 12|4@1+ (1,0) [0|15] "" Vector__XXX
 SG_ APSB_B_forcePowerOffRequest : 16|1@1+ (1,0) [0|1] "" Vector__XXX

BO_ 1864 APSB_state: 6 APSB
 SG_ APSB_primaryTurbo : 0|2@1+ (1,0) [0|3] "" Vector__XXX
 SG_ APSB_A_arbState : 2|3@1+ (1,0) [0|7] "" Vector__XXX
 SG_ APSB_A_powerState : 5|5@1+ (1,0) [0|31] "" Vector__XXX
 SG_ APSB_A_sleepState : 10|4@1+ (1,0) [0|15] "" Vector__XXX
 SG_ APSB_A_resetState : 14|3@1+ (1,0) [0|7] "" Vector__XXX
 SG_ APSB_A_faultState : 17|5@1+ (1,0) [0|31] "" Vector__XXX
 SG_ APSB_secondaryTurbo : 22|2@1+ (1,0) [0|3] "" Vector__XXX
 SG_ APSB_B_arbState : 24|3@1+ (1,0) [0|7] "" Vector__XXX
 SG_ APSB_B_powerState : 27|5@1+ (1,0) [0|31] "" Vector__XXX
 SG_ APSB_B_sleepState : 32|4@1+ (1,0) [0|15] "" Vector__XXX
 SG_ APSB_B_resetState : 36|3@1+ (1,0) [0|7] "" Vector__XXX
 SG_ APSB_B_faultState : 39|5@1+ (1,0) [0|31] "" Vector__XXX
 SG_ APSB_stateCounter : 44|4@1+ (1,0) [0|15] "" Vector__XXX

BO_ 971 APSB_status: 8 APSB
 SG_ APSB_appStatusMonitorState : 0|3@1+ (1,0) [0|7] "" Vector__XXX
 SG_ APSB_vehBehaviorState : 4|4@1+ (1,0) [0|15] "" Vector__XXX
 SG_ APSB_canMaster : 8|2@1+ (1,0) [0|2] "" Vector__XXX
 SG_ APSB_appGpioState : 10|2@1+ (1,0) [0|3] "" Vector__XXX
 SG_ APSB_eacInternalState : 12|3@1+ (1,0) [0|7] "" Vector__XXX
 SG_ APSB_switchState : 15|1@1+ (1,0) [0|1] "" Vector__XXX
 SG_ APSB_apbStatusMonitorState : 16|3@1+ (1,0) [0|7] "" Vector__XXX
 SG_ APSB_apbGpioState : 20|2@1+ (1,0) [0|3] "" Vector__XXX
 SG_ APSB_statusCounter : 22|4@1+ (1,0) [0|15] "" Vector__XXX
 SG_ APSB_locLimitReason : 26|3@1+ (1,0) [0|7] "" Vector__XXX
 SG_ APSB_appPowerStateRequest : 29|2@1+ (1,0) [0|3] "" Vector__XXX
 SG_ APSB_appPowerStateReason : 31|4@1+ (1,0) [0|15] "" Vector__XXX
 SG_ APSB_apbPowerStateRequest : 36|2@1+ (1,0) [0|3] "" Vector__XXX
 SG_ APSB_apbPowerStateReason : 38|4@1+ (1,0) [0|15] "" Vector__XXX
 SG_ APSB_heaterStateDebug : 43|3@1+ (1,0) [0|6] "" Vector__XXX
 SG_ APSB_autosummonCounter : 46|3@1+ (1,0) [0|7] "" Vector__XXX
 SG_ APSB_autosummonAlert : 49|1@1+ (1,0) [0|1] "" Vector__XXX
 SG_ APSB_gpsAntennaState : 50|2@1+ (1,0) [0|3] "" Vector__XXX
 SG_ APSB_arbState : 52|3@1+ (1,0) [0|7] "" Vector__XXX
 SG_ APSB_socPowerOperatingMode : 55|2@1+ (1,0) [0|3] "" Vector__XXX

BO_TX_BU_ 809 : APP;
BO_TX_BU_ 873 : APP;
BO_TX_BU_ 1065 : APP;
BO_TX_BU_ 1081 : APP;
BO_TX_BU_ 1097 : APP;
BO_TX_BU_ 1145 : APP;
BO_TX_BU_ 1149 : APP;
BO_TX_BU_ 992 : APSB;
BO_TX_BU_ 1864 : APSB;
BO_TX_BU_ 971 : APSB;
CM_ BO_ 809 "Driver assistance computer (primary) message: warning matrix0";
CM_ SG_ 809 APP_w001_DEPRECATED "Driver assistance computer (primary): w001 DEPRECATED";
CM_ SG_ 809 APP_w002_ldwDisabled "Driver assistance computer (primary): w002 ldw disabled";
CM_ SG_ 809 APP_w003_isaDisabled "Driver assistance computer (primary): w003 isa disabled";
CM_ SG_ 809 APP_w004_accDisabled "Driver assistance computer (primary): w004 acc disabled";
CM_ SG_ 809 APP_w005_fcwCancelled "Driver assistance computer (primary): w005 fcw cancelled";
CM_ SG_ 809 APP_w006_aebCancelled "Driver assistance computer (primary): w006 aeb cancelled";
CM_ SG_ 809 APP_w007_ahlbDisabled "Driver assistance computer (primary): w007 ahlb disabled";
CM_ SG_ 809 APP_w008_parkDisabled "Driver assistance computer (primary): w008 park disabled";
CM_ SG_ 809 APP_w009_aebFault "Driver assistance computer (primary): w009 aeb fault";
CM_ SG_ 809 APP_w010_radcCalibIssue "Driver assistance computer (primary): w010 radc calib issue";
CM_ SG_ 809 APP_w011_scaEvent "Driver assistance computer (primary): w011 sca event";
CM_ SG_ 809 APP_w012_Cam_BootFailure "Driver assistance computer (primary): w012 cam boot failure";
CM_ SG_ 809 APP_w013_Cam_Watchdog "Driver assistance computer (primary): w013 cam watchdog";
CM_ SG_ 809 APP_w014_swAssert "Driver assistance computer (primary): w014 sw assert";
CM_ SG_ 809 APP_w015_Camera_Failsafes "Driver assistance computer (primary): w015 camera failsafes";
CM_ SG_ 809 APP_w016_aeb_e_event "Driver assistance computer (primary): w016 aeb e event";
CM_ SG_ 809 APP_w017_Cam_Msg_MIA "Driver assistance computer (primary): w017 cam msg MIA";
CM_ SG_ 809 APP_w018_ECU_Power_Issue "Driver assistance computer (primary): w018 ECU power issue";
CM_ SG_ 809 APP_w019_ECU_Stack_Overflow "Driver assistance computer (primary): w019 ECU stack overflow";
CM_ SG_ 809 APP_w020_ECU_checkstopError "Driver assistance computer (primary): w020 ECU checkstop error";
CM_ SG_ 809 APP_w021_ECU_Temperature_Issue "Driver assistance computer (primary): w021 ECU temperature issue";
CM_ SG_ 809 APP_w022_ECU_EEPROM_Failure "Driver assistance computer (primary): w022 ECU EEPROM failure";
CM_ SG_ 809 APP_w023_ECU_Cam_Statemismatc "Driver assistance computer (primary): w023 ECU cam statemismatc";
CM_ SG_ 809 APP_w024_ECU_Watchdog_Reset "Driver assistance computer (primary): w024 ECU watchdog reset";
CM_ SG_ 809 APP_w025_LC_Steering_Override "Driver assistance computer (primary): w025 LC steering override";
CM_ SG_ 809 APP_w026_ECU_timingIssue "Driver assistance computer (primary): w026 ECU timing issue";
CM_ SG_ 809 APP_w027_ECU_Reset_Fault "Driver assistance computer (primary): w027 ECU reset fault";
CM_ SG_ 809 APP_w028_spi_rx_error "Driver assistance computer (primary): w028 spi rx error";
CM_ SG_ 809 APP_w029_spi_tx_error "Driver assistance computer (primary): w029 spi tx error";
CM_ SG_ 809 APP_w030_Heater_Issue "Driver assistance computer (primary): w030 heater issue";
CM_ SG_ 809 APP_w031_canRxError "Driver assistance computer (primary): w031 can rx error";
CM_ SG_ 809 APP_w032_canTxError "Driver assistance computer (primary): w032 can tx error";
CM_ SG_ 809 APP_w033_gtwMia "Driver assistance computer (primary): w033 gtw mia";
CM_ SG_ 809 APP_w034_sccmMia "Driver assistance computer (primary): w034 sccm mia";
CM_ SG_ 809 APP_w035_espMia "Driver assistance computer (primary): w035 esp mia";
CM_ SG_ 809 APP_w036_bdyMia "Driver assistance computer (primary): w036 bdy mia";
CM_ SG_ 809 APP_w037_camTacIssue "Driver assistance computer (primary): w037 cam tac issue";
CM_ SG_ 809 APP_w038_camFailure "Driver assistance computer (primary): w038 cam failure";
CM_ SG_ 809 APP_w039_sdm_rcm_Mia "Driver assistance computer (primary): w039 sdm rcm mia";
CM_ SG_ 809 APP_w040_autopilotAngleSaturated "Driver assistance computer (primary): w040 autopilot angle saturated";
CM_ SG_ 809 APP_w041_autopilotRateSaturated "Driver assistance computer (primary): w041 autopilot rate saturated";
CM_ SG_ 809 APP_w042_autopilotAborting "Driver assistance computer (primary): w042 autopilot aborting";
CM_ SG_ 809 APP_w043_camLongRunTime "Driver assistance computer (primary): w043 cam long run time";
CM_ SG_ 809 APP_w044_appMobileyeFailure "Driver assistance computer (primary): w044 app mobileye failure";
CM_ SG_ 809 APP_w045_radMia "Driver assistance computer (primary): w045 rad mia";
CM_ SG_ 809 APP_w046_eepromRecordAbsent "Driver assistance computer (primary): w046 eeprom record absent";
CM_ SG_ 809 APP_w047_edrEvent "Driver assistance computer (primary): w047 edr event";
CM_ SG_ 809 APP_w048_APP_Features_Disabled "Driver assistance computer (primary): w048 APP features disabled";
CM_ SG_ 809 APP_w049_eyeqVersionMismatch "Driver assistance computer (primary): w049 eyeq version mismatch";
CM_ SG_ 809 APP_w050_aeb_event "Driver assistance computer (primary): w050 aeb event";
CM_ SG_ 809 APP_w051_radcEcuIssue "Driver assistance computer (primary): w051 radc ecu issue";
CM_ SG_ 809 APP_w052_radcSensorIssue "Driver assistance computer (primary): w052 radc sensor issue";
CM_ SG_ 809 APP_w053_radcCommIssue "Driver assistance computer (primary): w053 radc comm issue";
CM_ SG_ 809 APP_w054_camAutofix "Driver assistance computer (primary): w054 cam autofix";
CM_ SG_ 809 APP_w055_radcVersionMismatch "Driver assistance computer (primary): w055 radc version mismatch";
CM_ SG_ 809 APP_w056_diMia "Driver assistance computer (primary): w056 di mia";
CM_ SG_ 809 APP_w057_mcuMia "Driver assistance computer (primary): w057 mcu mia";
CM_ SG_ 809 APP_w058_epbMia "Driver assistance computer (primary): w058 epb mia";
CM_ SG_ 809 APP_w059_parkMia "Driver assistance computer (primary): w059 park mia";
CM_ SG_ 809 APP_w060_fcw_event "Driver assistance computer (primary): w060 fcw event";
CM_ SG_ 809 APP_w061_airSuspensionMia "Driver assistance computer (primary): w061 air suspension mia";
CM_ SG_ 809 APP_w062_radcAlignment "Driver assistance computer (primary): w062 radc alignment";
CM_ SG_ 809 APP_w063_parkVersionMismatch "Driver assistance computer (primary): w063 park version mismatch";
CM_ SG_ 809 APP_w064_epasMia "Driver assistance computer (primary): w064 epas mia";
CM_ BO_ 873 "Driver assistance computer (primary) message: warning matrix1";
CM_ SG_ 873 APP_w065_deserializerOvercurrent "Driver assistance computer (primary): w065 deserializer overcurrent";
CM_ SG_ 873 APP_w066_deserializerLockLost "Driver assistance computer (primary): w066 deserializer lock lost";
CM_ SG_ 873 APP_w067_steeringAlignment "Driver assistance computer (primary): w067 steering alignment";
CM_ SG_ 873 APP_w068_vlInconsistency "Driver assistance computer (primary): w068 vl inconsistency";
CM_ SG_ 873 APP_w069_apcSpaceMasked "Driver assistance computer (primary): w069 apc space masked";
CM_ SG_ 873 APP_w070_apcIncompleteCal "Driver assistance computer (primary): w070 apc incomplete cal";
CM_ SG_ 873 APP_w071_selfparkStarted "Driver assistance computer (primary): w071 selfpark started";
CM_ SG_ 873 APP_w072_selfparkComplete "Driver assistance computer (primary): w072 selfpark complete";
CM_ SG_ 873 APP_w073_issueEscalatedLDW "Driver assistance computer (primary): w073 issue escalated LDW";
CM_ SG_ 873 APP_w074_inPathStationaryObst "Driver assistance computer (primary): w074 in path stationary obst";
CM_ SG_ 873 APP_w075_scMia "Driver assistance computer (primary): w075 sc mia";
CM_ SG_ 873 APP_w076_mobilEyeSetC "Driver assistance computer (primary): w076 mobil eye set c";
CM_ SG_ 873 APP_w077_pmmActive "Driver assistance computer (primary): w077 pmm active";
CM_ SG_ 873 APP_w078_pmmActive2 "Driver assistance computer (primary): w078 pmm active2";
CM_ SG_ 873 APP_w079_edrAvailable "Driver assistance computer (primary): w079 edr available";
CM_ SG_ 873 APP_w080_accFailedActivation "Driver assistance computer (primary): w080 acc failed activation";
CM_ SG_ 873 APP_w081_pmmActiveBraking "Driver assistance computer (primary): w081 pmm active braking";
CM_ SG_ 873 APP_w082_inPathFSviolation "Driver assistance computer (primary): w082 in path f sviolation";
CM_ SG_ 873 APP_w083_inPathRADObject "Driver assistance computer (primary): w083 in path RAD object";
CM_ SG_ 873 APP_w084_pmmIPSO "Driver assistance computer (primary): w084 pmm IPSO";
CM_ SG_ 873 APP_w085_pmmSteering "Driver assistance computer (primary): w085 pmm steering";
CM_ SG_ 873 APP_w086_robCollision "Driver assistance computer (primary): w086 rob collision";
CM_ SG_ 873 APP_w087_DEPRECATED "Driver assistance computer (primary): w087 DEPRECATED";
CM_ SG_ 873 APP_w088_DEPRECATED "Driver assistance computer (primary): w088 DEPRECATED";
CM_ SG_ 873 APP_w089_DEPRECATED "Driver assistance computer (primary): w089 DEPRECATED";
CM_ SG_ 873 APP_w090_DEPRECATED "Driver assistance computer (primary): w090 DEPRECATED";
CM_ SG_ 873 APP_w091_DEPRECATED "Driver assistance computer (primary): w091 DEPRECATED";
CM_ SG_ 873 APP_w092_DEPRECATED "Driver assistance computer (primary): w092 DEPRECATED";
CM_ SG_ 873 APP_w093_DEPRECATED "Driver assistance computer (primary): w093 DEPRECATED";
CM_ SG_ 873 APP_w094_DEPRECATED "Driver assistance computer (primary): w094 DEPRECATED";
CM_ SG_ 873 APP_w095_DEPRECATED "Driver assistance computer (primary): w095 DEPRECATED";
CM_ SG_ 873 APP_w096_DEPRECATED "Driver assistance computer (primary): w096 DEPRECATED";
CM_ SG_ 873 APP_w097_DEPRECATED "Driver assistance computer (primary): w097 DEPRECATED";
CM_ SG_ 873 APP_w098_DEPRECATED "Driver assistance computer (primary): w098 DEPRECATED";
CM_ SG_ 873 APP_w099_DEPRECATED "Driver assistance computer (primary): w099 DEPRECATED";
CM_ SG_ 873 APP_w100_DEPRECATED "Driver assistance computer (primary): w100 DEPRECATED";
CM_ SG_ 873 APP_w101_DEPRECATED "Driver assistance computer (primary): w101 DEPRECATED";
CM_ SG_ 873 APP_w102_DEPRECATED "Driver assistance computer (primary): w102 DEPRECATED";
CM_ SG_ 873 APP_w103_robExperimentalAEB "Driver assistance computer (primary): w103 rob experimental AEB";
CM_ SG_ 873 APP_w104_DEPRECATED "Driver assistance computer (primary): w104 DEPRECATED";
CM_ SG_ 873 APP_w105_DEPRECATED "Driver assistance computer (primary): w105 DEPRECATED";
CM_ SG_ 873 APP_w106_torsionBarOffset "Driver assistance computer (primary): w106 torsion bar offset";
CM_ BO_ 1065 "Driver assistance computer (primary) message: warning matrix2";
CM_ SG_ 1065 APP_w129_mainCamExtNotCal "Driver assistance computer (primary): w129 main cam ext not cal";
CM_ SG_ 1065 APP_w130_narrowCamExtNotCal "Driver assistance computer (primary): w130 narrow cam ext not cal";
CM_ SG_ 1065 APP_w131_mainCamCalSaved "Driver assistance computer (primary): w131 main cam cal saved";
CM_ SG_ 1065 APP_w132_narrowCamCalSaved "Driver assistance computer (primary): w132 narrow cam cal saved";
CM_ SG_ 1065 APP_w133_mainCamInitFault "Driver assistance computer (primary): w133 main cam init fault";
CM_ SG_ 1065 APP_w134_narrowCamInitFault "Driver assistance computer (primary): w134 narrow cam init fault";
CM_ SG_ 1065 APP_w135_fisheyeCamInitFault "Driver assistance computer (primary): w135 fisheye cam init fault";
CM_ SG_ 1065 APP_w136_lPillarCamInitFault "Driver assistance computer (primary): w136 l pillar cam init fault";
CM_ SG_ 1065 APP_w137_rPillarCamInitFault "Driver assistance computer (primary): w137 r pillar cam init fault";
CM_ SG_ 1065 APP_w138_lRepeatCamInitFault "Driver assistance computer (primary): w138 l repeat cam init fault";
CM_ SG_ 1065 APP_w139_rRepeatCamInitFault "Driver assistance computer (primary): w139 r repeat cam init fault";
CM_ SG_ 1065 APP_w140_backupCamInitFault "Driver assistance computer (primary): w140 backup cam init fault";
CM_ SG_ 1065 APP_w141_ECU_Thermal_Issue "Driver assistance computer (primary): w141 ECU thermal issue";
CM_ SG_ 1065 APP_w142_fwdCamPitchProblem "Driver assistance computer (primary): w142 fwd cam pitch problem";
CM_ SG_ 1065 APP_w143_IDF_event "Driver assistance computer (primary): w143 IDF event";
CM_ SG_ 1065 APP_w144_fanctrldError "Driver assistance computer (primary): w144 fanctrld error";
CM_ SG_ 1065 APP_w145_camSelfCalIssue "Driver assistance computer (primary): w145 cam self cal issue";
CM_ SG_ 1065 APP_w146_telemetryProblem "Driver assistance computer (primary): w146 telemetry problem";
CM_ SG_ 1065 APP_w147_selfieCamInitFault "Driver assistance computer (primary): w147 selfie cam init fault";
CM_ SG_ 1065 APP_w148_overlayActive "Driver assistance computer (primary): w148 overlay active";
CM_ SG_ 1065 APP_w149_diskFull "Driver assistance computer (primary): w149 disk full";
CM_ SG_ 1065 APP_w150_diMiaPartyBus "Driver assistance computer (primary): w150 di mia party bus";
CM_ SG_ 1065 APP_w151_epasMiaPartyBus "Driver assistance computer (primary): w151 epas mia party bus";
CM_ SG_ 1065 APP_w152_espMiaPartyBus "Driver assistance computer (primary): w152 esp mia party bus";
CM_ SG_ 1065 APP_w153_rcmMiaPartyBus "Driver assistance computer (primary): w153 rcm mia party bus";
CM_ SG_ 1065 APP_w154_vcleftMiaPartyBus "Driver assistance computer (primary): w154 vcleft mia party bus";
CM_ SG_ 1065 APP_w155_vcrightMiaPartyBus "Driver assistance computer (primary): w155 vcright mia party bus";
CM_ SG_ 1065 APP_w156_epblMiaVehBus "Driver assistance computer (primary): w156 epbl mia veh bus";
CM_ SG_ 1065 APP_w157_sccmMiaVehBus "Driver assistance computer (primary): w157 sccm mia veh bus";
CM_ SG_ 1065 APP_w158_vcfrontMiaVehBus "Driver assistance computer (primary): w158 vcfront mia veh bus";
CM_ SG_ 1065 APP_w159_vcleftMiaVehBus "Driver assistance computer (primary): w159 vcleft mia veh bus";
CM_ SG_ 1065 APP_w160_vcrightMiaVehBus "Driver assistance computer (primary): w160 vcright mia veh bus";
CM_ SG_ 1065 APP_w161_backupCameraUnavailable "Driver assistance computer (primary): w161 backup camera unavailable";
CM_ SG_ 1065 APP_w162_mainCameraTypeError "Driver assistance computer (primary): w162 main camera type error";
CM_ SG_ 1065 APP_w163_narrowCameraTypeError "Driver assistance computer (primary): w163 narrow camera type error";
CM_ SG_ 1065 APP_w164_fisheyeCameraTypeError "Driver assistance computer (primary): w164 fisheye camera type error";
CM_ SG_ 1065 APP_w165_lPillarCameraTypeError "Driver assistance computer (primary): w165 l pillar camera type error";
CM_ SG_ 1065 APP_w166_rPillarCameraTypeError "Driver assistance computer (primary): w166 r pillar camera type error";
CM_ SG_ 1065 APP_w167_lRepeatCameraTypeError "Driver assistance computer (primary): w167 l repeat camera type error";
CM_ SG_ 1065 APP_w168_rRepeatCameraTypeError "Driver assistance computer (primary): w168 r repeat camera type error";
CM_ SG_ 1065 APP_w169_backupCameraTypeError "Driver assistance computer (primary): w169 backup camera type error";
CM_ SG_ 1065 APP_w170_selfieCameraTypeError "Driver assistance computer (primary): w170 selfie camera type error";
CM_ SG_ 1065 APP_w171_appHighCoolantFlowReq "Driver assistance computer (primary): w171 app high coolant flow req";
CM_ SG_ 1065 APP_w172_fisheyeCamExtNotCal "Driver assistance computer (primary): w172 fisheye cam ext not cal";
CM_ SG_ 1065 APP_w173_lPillarCamExtNotCal "Driver assistance computer (primary): w173 l pillar cam ext not cal";
CM_ SG_ 1065 APP_w174_rPillarCamExtNotCal "Driver assistance computer (primary): w174 r pillar cam ext not cal";
CM_ SG_ 1065 APP_w175_lRepeatCamExtNotCal "Driver assistance computer (primary): w175 l repeat cam ext not cal";
CM_ SG_ 1065 APP_w176_rRepeatCamExtNotCal "Driver assistance computer (primary): w176 r repeat cam ext not cal";
CM_ SG_ 1065 APP_w177_fisheyeCamCalSaved "Driver assistance computer (primary): w177 fisheye cam cal saved";
CM_ SG_ 1065 APP_w178_lPillarCamCalSaved "Driver assistance computer (primary): w178 l pillar cam cal saved";
CM_ SG_ 1065 APP_w179_rPillarCamCalSaved "Driver assistance computer (primary): w179 r pillar cam cal saved";
CM_ SG_ 1065 APP_w180_lRepeatCamCalSaved "Driver assistance computer (primary): w180 l repeat cam cal saved";
CM_ SG_ 1065 APP_w181_rRepeatCamCalSaved "Driver assistance computer (primary): w181 r repeat cam cal saved";
CM_ SG_ 1065 APP_w182_mainCameraStreamExit "Driver assistance computer (primary): w182 main camera stream exit";
CM_ SG_ 1065 APP_w183_narrowCameraStreamExit "Driver assistance computer (primary): w183 narrow camera stream exit";
CM_ SG_ 1065 APP_w184_fisheyeCameraStreamExit "Driver assistance computer (primary): w184 fisheye camera stream exit";
CM_ SG_ 1065 APP_w185_lPillarCameraStreamExit "Driver assistance computer (primary): w185 l pillar camera stream exit";
CM_ SG_ 1065 APP_w186_rPillarCameraStreamExit "Driver assistance computer (primary): w186 r pillar camera stream exit";
CM_ SG_ 1065 APP_w187_lRepeatCameraStreamExit "Driver assistance computer (primary): w187 l repeat camera stream exit";
CM_ SG_ 1065 APP_w188_rRepeatCameraStreamExit "Driver assistance computer (primary): w188 r repeat camera stream exit";
CM_ SG_ 1065 APP_w189_backupCameraStreamExit "Driver assistance computer (primary): w189 backup camera stream exit";
CM_ SG_ 1065 APP_w190_selfieCameraStreamExit "Driver assistance computer (primary): w190 selfie camera stream exit";
CM_ SG_ 1065 APP_w191_autopilotAborting "Driver assistance computer (primary): w191 autopilot aborting";
CM_ SG_ 1065 APP_w192_emergencySpeakerFail "Driver assistance computer (primary): w192 emergency speaker fail";
CM_ BO_ 1081 "Driver assistance computer (primary) message: warning matrix3";
CM_ SG_ 1081 APP_w193_camWindshieldUnclean "Driver assistance computer (primary): w193 cam windshield unclean";
CM_ SG_ 1081 APP_w194_accDriverResumeRqrd "Driver assistance computer (primary): w194 acc driver resume rqrd";
CM_ SG_ 1081 APP_w195_scwUnavailable "Driver assistance computer (primary): w195 scw unavailable";
CM_ SG_ 1081 APP_w196_stopSignWarning "Driver assistance computer (primary): w196 stop sign warning";
CM_ SG_ 1081 APP_w197_redLightWarning "Driver assistance computer (primary): w197 red light warning";
CM_ SG_ 1081 APP_w198_tsrUnavailable "Driver assistance computer (primary): w198 tsr unavailable";
CM_ SG_ 1081 APP_w199_apcAbort "Driver assistance computer (primary): w199 apc abort";
CM_ SG_ 1081 APP_w200_lcSlowdown "Driver assistance computer (primary): w200 lc slowdown";
CM_ SG_ 1081 APP_w201_lcAborting "Driver assistance computer (primary): w201 lc aborting";
CM_ SG_ 1081 APP_w202_scwNoisyEnvironment "Driver assistance computer (primary): w202 scw noisy environment";
CM_ SG_ 1081 APP_w203_apcActivation "Driver assistance computer (primary): w203 apc activation";
CM_ SG_ 1081 APP_w204_apcFinalFront "Driver assistance computer (primary): w204 apc final front";
CM_ SG_ 1081 APP_w205_apcFinalRear "Driver assistance computer (primary): w205 apc final rear";
CM_ SG_ 1081 APP_w206_autosteerNotEnabled "Driver assistance computer (primary): w206 autosteer not enabled";
CM_ SG_ 1081 APP_w207_autosteerUnavailable "Driver assistance computer (primary): w207 autosteer unavailable";
CM_ SG_ 1081 APP_w208_rackDetected "Driver assistance computer (primary): w208 rack detected";
CM_ SG_ 1081 APP_w209_autoSummonRequest "Driver assistance computer (primary): w209 auto summon request";
CM_ SG_ 1081 APP_w210_camObstrcted "Driver assistance computer (primary): w210 cam obstrcted";
CM_ SG_ 1081 APP_w211_accNoSeatBelt "Driver assistance computer (primary): w211 acc no seat belt";
CM_ SG_ 1081 APP_w212_lcUnavailableStrikeOut "Driver assistance computer (primary): w212 lc unavailable strike out";
CM_ SG_ 1081 APP_w213_autosteerStruckOut "Driver assistance computer (primary): w213 autosteer struck out";
CM_ SG_ 1081 APP_w214_driverNotIntracting "Driver assistance computer (primary): w214 driver not intracting";
CM_ SG_ 1081 APP_w215_contDriverNotIntracting "Driver assistance computer (primary): w215 cont driver not intracting";
CM_ SG_ 1081 APP_w216_driverOverriding "Driver assistance computer (primary): w216 driver overriding";
CM_ SG_ 1081 APP_w217_lcUnavailableSpeeding "Driver assistance computer (primary): w217 lc unavailable speeding";
CM_ SG_ 1081 APP_w218_lcSpeedExceededLimit "Driver assistance computer (primary): w218 lc speed exceeded limit";
CM_ SG_ 1081 APP_w219_lcTempUnavailableSpeed "Driver assistance computer (primary): w219 lc temp unavailable speed";
CM_ SG_ 1081 APP_w220_lcTempUnavailableRoad "Driver assistance computer (primary): w220 lc temp unavailable road";
CM_ SG_ 1081 APP_w221_accRadarBlind "Driver assistance computer (primary): w221 acc radar blind";
CM_ SG_ 1081 APP_w222_accCameraBlind "Driver assistance computer (primary): w222 acc camera blind";
CM_ SG_ 1081 APP_w223_accObjectInPath "Driver assistance computer (primary): w223 acc object in path";
CM_ SG_ 1081 APP_w224_accCameraCalibration "Driver assistance computer (primary): w224 acc camera calibration";
CM_ SG_ 1081 APP_w225_lcDegradedVisSpeedLmt "Driver assistance computer (primary): w225 lc degraded vis speed lmt";
CM_ SG_ 1081 APP_w226_lcCamCalNeededSpeedLmt "Driver assistance computer (primary): w226 lc cam cal needed speed lmt";
CM_ SG_ 1081 APP_w227_virtualWallBlocked "Driver assistance computer (primary): w227 virtual wall blocked";
CM_ SG_ 1081 APP_w228_DEPRECATED "Driver assistance computer (primary): w228 DEPRECATED";
CM_ SG_ 1081 APP_w229_alcUltrasoundDamaged "Driver assistance computer (primary): w229 alc ultrasound damaged";
CM_ SG_ 1081 APP_w230_alcUltrasoundBlocked "Driver assistance computer (primary): w230 alc ultrasound blocked";
CM_ SG_ 1081 APP_w231_idfEvent "Driver assistance computer (primary): w231 idf event";
CM_ SG_ 1081 APP_w232_laneChangeRequested "Driver assistance computer (primary): w232 lane change requested";
CM_ SG_ 1081 APP_w234_activeSafetyTelemetry "Driver assistance computer (primary): w234 active safety telemetry";
CM_ BO_ 1097 "Driver assistance computer (primary) message: warning matrix4";
CM_ SG_ 1097 APP_w257_brakeJerkEvent "Driver assistance computer (primary): w257 brake jerk event";
CM_ SG_ 1097 APP_w258_aebEvent "Driver assistance computer (primary): w258 aeb event";
CM_ SG_ 1097 APP_w259_aebOverrideEvent "Driver assistance computer (primary): w259 aeb override event";
CM_ SG_ 1097 APP_w260_collisionWarningEvent "Driver assistance computer (primary): w260 collision warning event";
CM_ SG_ 1097 APP_w261_pcieHardwareErrors "Driver assistance computer (primary): w261 pcie hardware errors";
CM_ SG_ 1097 APP_w262_apeCalibMode "Driver assistance computer (primary): w262 ape calib mode";
CM_ SG_ 1097 APP_w263_lssAbort "Driver assistance computer (primary): w263 lss abort";
CM_ SG_ 1097 APP_w264_lssFault "Driver assistance computer (primary): w264 lss fault";
CM_ SG_ 1097 APP_w265_drvOnNavUnavailable "Driver assistance computer (primary): w265 drv on nav unavailable";
CM_ SG_ 1097 APP_w266_visionScheduleFallback "Driver assistance computer (primary): w266 vision schedule fallback";
CM_ SG_ 1097 APP_w267_benchtopEcu "Driver assistance computer (primary): w267 benchtop ecu";
CM_ SG_ 1097 APP_w268_backupCamExtNotCal "Driver assistance computer (primary): w268 backup cam ext not cal";
CM_ SG_ 1097 APP_w269_autopilotLimited "Driver assistance computer (primary): w269 autopilot limited";
CM_ SG_ 1097 APP_w270_blindspotRestricted "Driver assistance computer (primary): w270 blindspot restricted";
CM_ SG_ 1097 APP_w271_laneChangeAborted "Driver assistance computer (primary): w271 lane change aborted";
CM_ SG_ 1097 APP_w272_laneChangeUnavailable "Driver assistance computer (primary): w272 lane change unavailable";
CM_ SG_ 1097 APP_w273_lssEvent "Driver assistance computer (primary): w273 lss event";
CM_ SG_ 1097 APP_w274_mainCameraStreamErr "Driver assistance computer (primary): w274 main camera stream err";
CM_ SG_ 1097 APP_w275_narrowCameraStreamErr "Driver assistance computer (primary): w275 narrow camera stream err";
CM_ SG_ 1097 APP_w276_fisheyeCameraStreamErr "Driver assistance computer (primary): w276 fisheye camera stream err";
CM_ SG_ 1097 APP_w277_lPillarCameraStreamErr "Driver assistance computer (primary): w277 l pillar camera stream err";
CM_ SG_ 1097 APP_w278_rPillarCameraStreamErr "Driver assistance computer (primary): w278 r pillar camera stream err";
CM_ SG_ 1097 APP_w279_lRepeatCameraStreamErr "Driver assistance computer (primary): w279 l repeat camera stream err";
CM_ SG_ 1097 APP_w280_rRepeatCameraStreamErr "Driver assistance computer (primary): w280 r repeat camera stream err";
CM_ SG_ 1097 APP_w281_backupCameraStreamErr "Driver assistance computer (primary): w281 backup camera stream err";
CM_ SG_ 1097 APP_w282_selfieCameraStreamErr "Driver assistance computer (primary): w282 selfie camera stream err";
CM_ SG_ 1097 APP_w283_enhancedSummonAbort "Driver assistance computer (primary): w283 enhanced summon abort";
CM_ SG_ 1097 APP_w284_gpsAntennaDisconnected "Driver assistance computer (primary): w284 gps antenna disconnected";
CM_ SG_ 1097 APP_w285_gpsFaultReset "Driver assistance computer (primary): w285 gps fault reset";
CM_ SG_ 1097 APP_w286_gpsComIssue "Driver assistance computer (primary): w286 gps com issue";
CM_ SG_ 1097 APP_w287_gpsFusionStatus "Driver assistance computer (primary): w287 gps fusion status";
CM_ SG_ 1097 APP_w288_trafficLightWarning "Driver assistance computer (primary): w288 traffic light warning";
CM_ SG_ 1097 APP_w289_dramCorrEccErrors "Driver assistance computer (primary): w289 dram corr ecc errors";
CM_ SG_ 1097 APP_w290_dramUncorrEccErrors "Driver assistance computer (primary): w290 dram uncorr ecc errors";
CM_ SG_ 1097 APP_w291_stopSignWarning "Driver assistance computer (primary): w291 stop sign warning";
CM_ SG_ 1097 APP_w293_mainCameraSyncFailed "Driver assistance computer (primary): w293 main camera sync failed";
CM_ SG_ 1097 APP_w294_narrowCameraSyncFailed "Driver assistance computer (primary): w294 narrow camera sync failed";
CM_ SG_ 1097 APP_w295_fisheyeCameraSyncFailed "Driver assistance computer (primary): w295 fisheye camera sync failed";
CM_ SG_ 1097 APP_w296_lPillarCameraSyncFailed "Driver assistance computer (primary): w296 l pillar camera sync failed";
CM_ SG_ 1097 APP_w297_rPillarCameraSyncFailed "Driver assistance computer (primary): w297 r pillar camera sync failed";
CM_ SG_ 1097 APP_w298_lRepeatCameraSyncFailed "Driver assistance computer (primary): w298 l repeat camera sync failed";
CM_ SG_ 1097 APP_w299_rRepeatCameraSyncFailed "Driver assistance computer (primary): w299 r repeat camera sync failed";
CM_ SG_ 1097 APP_w300_backupCameraSyncFailed "Driver assistance computer (primary): w300 backup camera sync failed";
CM_ SG_ 1097 APP_w301_selfieCameraSyncFailed "Driver assistance computer (primary): w301 selfie camera sync failed";
CM_ SG_ 1097 APP_w302_vcfrontMiaPartyBus "Driver assistance computer (primary): w302 vcfront mia party bus";
CM_ SG_ 1097 APP_w303_imuIrational "Driver assistance computer (primary): w303 imu irational";
CM_ SG_ 1097 APP_w304_lssCamBlockedStatus "Driver assistance computer (primary): w304 lss cam blocked status";
CM_ SG_ 1097 APP_w305_lssCamStreamExit "Driver assistance computer (primary): w305 lss cam stream exit";
CM_ SG_ 1097 APP_w306_lssUltrasonicsBlocked "Driver assistance computer (primary): w306 lss ultrasonics blocked";
CM_ SG_ 1097 APP_w307_lssTurnSignalFault "Driver assistance computer (primary): w307 lss turn signal fault";
CM_ SG_ 1097 APP_w308_iboosterMia "Driver assistance computer (primary): w308 ibooster mia";
CM_ SG_ 1097 APP_w309_selfieDisabledOnCar "Driver assistance computer (primary): w309 selfie disabled on car";
CM_ SG_ 1097 APP_w310_eth0FrameErrors "Driver assistance computer (primary): w310 eth0 frame errors";
CM_ SG_ 1097 APP_w311_eth1FrameErrors "Driver assistance computer (primary): w311 eth1 frame errors";
CM_ SG_ 1097 APP_w312_mainCamTypeMismatch "Driver assistance computer (primary): w312 main cam type mismatch";
CM_ SG_ 1097 APP_w313_narrowCamTypeMismatch "Driver assistance computer (primary): w313 narrow cam type mismatch";
CM_ SG_ 1097 APP_w314_fisheyeCamTypeMismatch "Driver assistance computer (primary): w314 fisheye cam type mismatch";
CM_ SG_ 1097 APP_w315_lPillarCamTypeMismatch "Driver assistance computer (primary): w315 l pillar cam type mismatch";
CM_ SG_ 1097 APP_w316_rPillarCamTypeMismatch "Driver assistance computer (primary): w316 r pillar cam type mismatch";
CM_ SG_ 1097 APP_w317_lRepeatCamTypeMismatch "Driver assistance computer (primary): w317 l repeat cam type mismatch";
CM_ SG_ 1097 APP_w318_rRepeatCamTypeMismatch "Driver assistance computer (primary): w318 r repeat cam type mismatch";
CM_ SG_ 1097 APP_w319_backupCamTypeMismatch "Driver assistance computer (primary): w319 backup cam type mismatch";
CM_ SG_ 1097 APP_w320_selfieCamTypeMismatch "Driver assistance computer (primary): w320 selfie cam type mismatch";
CM_ BO_ 1145 "Driver assistance computer (primary) message: warning matrix5";
CM_ SG_ 1145 APP_w321_bmsMia "Driver assistance computer (primary): w321 bms mia";
CM_ SG_ 1145 APP_w322_autoWiperWash "Driver assistance computer (primary): w322 auto wiper wash";
CM_ SG_ 1145 APP_w323_drivableSpaceFCW "Driver assistance computer (primary): w323 drivable space FCW";
CM_ SG_ 1145 APP_w324_adspMia "Driver assistance computer (primary): w324 adsp mia";
CM_ SG_ 1145 APP_w325_watchdogReset "Driver assistance computer (primary): w325 watchdog reset";
CM_ SG_ 1145 APP_w326_kernelPanic "Driver assistance computer (primary): w326 kernel panic";
CM_ SG_ 1145 APP_w327_vehicleConfigMismatch "Driver assistance computer (primary): w327 vehicle config mismatch";
CM_ SG_ 1145 APP_w328_autoparkDegraded "Driver assistance computer (primary): w328 autopark degraded";
CM_ SG_ 1145 APP_w329_evasiveManeuver "Driver assistance computer (primary): w329 evasive maneuver";
CM_ SG_ 1145 APP_w330_cabinCameraFault "Driver assistance computer (primary): w330 cabin camera fault";
CM_ SG_ 1145 APP_w331_fsdDegradedUnavailable "Driver assistance computer (primary): w331 fsd degraded unavailable";
CM_ SG_ 1145 APP_w332_cameraPositionsSwapped "Driver assistance computer (primary): w332 camera positions swapped";
CM_ SG_ 1145 APP_w333_fsdUnavailableLocation "Driver assistance computer (primary): w333 fsd unavailable location";
CM_ SG_ 1145 APP_w334_frontCameraOccluded "Driver assistance computer (primary): w334 front camera occluded";
CM_ SG_ 1145 APP_w335_tradfcRfSensorError "Driver assistance computer (primary): w335 tradfc rf sensor error";
CM_ SG_ 1145 APP_w336_tradfcLfPmicError "Driver assistance computer (primary): w336 tradfc lf pmic error";
CM_ SG_ 1145 APP_w337_tradfcRfPmicError "Driver assistance computer (primary): w337 tradfc rf pmic error";
CM_ SG_ 1145 APP_w338_tradfcLfTempError "Driver assistance computer (primary): w338 tradfc lf temp error";
CM_ SG_ 1145 APP_w339_tradfcRfTempError "Driver assistance computer (primary): w339 tradfc rf temp error";
CM_ SG_ 1145 APP_w340_tradfcCsiError "Driver assistance computer (primary): w340 tradfc csi error";
CM_ SG_ 1145 APP_w341_tradfcCalibError "Driver assistance computer (primary): w341 tradfc calib error";
CM_ SG_ 1145 APP_w342_tradfcDspHwError "Driver assistance computer (primary): w342 tradfc dsp hw error";
CM_ SG_ 1145 APP_w343_tradfcDspSwError "Driver assistance computer (primary): w343 tradfc dsp sw error";
CM_ SG_ 1145 APP_w344_tradfcDspAlgoTimeout "Driver assistance computer (primary): w344 tradfc dsp algo timeout";
CM_ SG_ 1145 APP_w345_tradfcPerfDegraded "Driver assistance computer (primary): w345 tradfc perf degraded";
CM_ SG_ 1145 APP_w346_gpsSwEvent "Driver assistance computer (primary): w346 gps sw event";
CM_ SG_ 1145 APP_w347_vcbattMiaVehBus "Driver assistance computer (primary): w347 vcbatt mia veh bus";
CM_ SG_ 1145 APP_w348_cameraSwUpdateRequired "Driver assistance computer (primary): w348 camera sw update required";
CM_ SG_ 1145 APP_w349_cameraPersistentlyFault "Driver assistance computer (primary): w349 camera persistently faulted";
CM_ SG_ 1145 APP_w350_tradfcSensorMisaligned "Driver assistance computer (primary): w350 tradfc sensor misaligned";
CM_ SG_ 1145 APP_w351_csiDevice0Down "Driver assistance computer (primary): w351 csi device0 down";
CM_ SG_ 1145 APP_w352_csiDevice1Down "Driver assistance computer (primary): w352 csi device1 down";
CM_ SG_ 1145 APP_w353_csiDevice2Down "Driver assistance computer (primary): w353 csi device2 down";
CM_ SG_ 1145 APP_w354_tradfcMia "Driver assistance computer (primary): w354 tradfc mia";
CM_ SG_ 1145 APP_w355_camQuadPowerFault "Driver assistance computer (primary): w355 cam quad power fault";
CM_ SG_ 1145 APP_w356_driverOverriding "Driver assistance computer (primary): w356 driver overriding";
CM_ SG_ 1145 APP_w357_ddawSystemFault "Driver assistance computer (primary): w357 ddaw system fault";
CM_ SG_ 1145 APP_w358_isaSystemFault "Driver assistance computer (primary): w358 isa system fault";
CM_ SG_ 1145 APP_w359_aebDegraded "Driver assistance computer (primary): w359 aeb degraded";
CM_ SG_ 1145 APP_w360_ApImuNoiseDetected "Driver assistance computer (primary): w360 ap imu noise detected";
CM_ SG_ 1145 APP_w361_cabinCameraLEDFault "Driver assistance computer (primary): w361 cabin camera LED fault";
CM_ SG_ 1145 APP_w362_fasciaCamInitFault "Driver assistance computer (primary): w362 fascia cam init fault";
CM_ SG_ 1145 APP_w363_fasciaCameraStreamExit "Driver assistance computer (primary): w363 fascia camera stream exit";
CM_ SG_ 1145 APP_w364_fasciaCameraTypeError "Driver assistance computer (primary): w364 fascia camera type error";
CM_ SG_ 1145 APP_w365_fasciaCamExtNotCal "Driver assistance computer (primary): w365 fascia cam ext not cal";
CM_ SG_ 1145 APP_w366_fasciaCameraSyncFailed "Driver assistance computer (primary): w366 fascia camera sync failed";
CM_ SG_ 1145 APP_w367_fasciaCamCalSaved "Driver assistance computer (primary): w367 fascia cam cal saved";
CM_ SG_ 1145 APP_w368_fasciaCamTypeMismatch "Driver assistance computer (primary): w368 fascia cam type mismatch";
CM_ SG_ 1145 APP_w369_cruiseWithSingleClick "Driver assistance computer (primary): w369 cruise with single click";
CM_ SG_ 1145 APP_w370_accApUnavUserSettings "Driver assistance computer (primary): w370 acc ap unav user settings";
CM_ SG_ 1145 APP_w371_networkLoadingIssue "Driver assistance computer (primary): w371 network loading issue";
CM_ SG_ 1145 APP_w372_cabinCameraBlocked "Driver assistance computer (primary): w372 cabin camera blocked";
CM_ SG_ 1145 APP_w373_gnssUartError "Driver assistance computer (primary): w373 gnss uart error";
CM_ SG_ 1145 APP_w374_gnssUartDataMia "Driver assistance computer (primary): w374 gnss uart data mia";
CM_ SG_ 1145 APP_w375_gnssPpsMia "Driver assistance computer (primary): w375 gnss pps mia";
CM_ SG_ 1145 APP_w376_wheeltickCountMia "Driver assistance computer (primary): w376 wheeltick count mia";
CM_ SG_ 1145 APP_w377_apImuMia "Driver assistance computer (primary): w377 ap imu mia";
CM_ SG_ 1145 APP_w378_ubloxImuMia "Driver assistance computer (primary): w378 ublox imu mia";
CM_ SG_ 1145 APP_w379_positioningEngineMia "Driver assistance computer (primary): w379 positioning engine mia";
CM_ SG_ 1145 APP_w380_gnssPpsTimestampIssue "Driver assistance computer (primary): w380 gnss pps timestamp issue";
CM_ SG_ 1145 APP_w381_apImuTimestampIssue "Driver assistance computer (primary): w381 ap imu timestamp issue";
CM_ SG_ 1145 APP_w382_ubloxImuTimestampIssue "Driver assistance computer (primary): w382 ublox imu timestamp issue";
CM_ SG_ 1145 APP_w383_manyApRebootsWhileInP "Driver assistance computer (primary): w383 many ap reboots while in p";
CM_ SG_ 1145 APP_w384_posEngineInitInMotion "Driver assistance computer (primary): w384 pos engine init in motion";
CM_ BO_ 1149 "Driver assistance computer (primary) message: warning matrix6";
CM_ SG_ 1149 APP_w385_posEngineUnhealthy "Driver assistance computer (primary): w385 pos engine unhealthy";
CM_ SG_ 1149 APP_w386_radarOnlyBrakingEvent "Driver assistance computer (primary): w386 radar only braking event";
CM_ SG_ 1149 APP_w387_radarBlockageDetected "Driver assistance computer (primary): w387 radar blockage detected";
CM_ SG_ 1149 APP_w388_windshieldCameraHeaterF "Driver assistance computer (primary): w388 windshield camera heater faulted";
CM_ SG_ 1149 APP_w389_camFovResidueDetected "Driver assistance computer (primary): w389 cam fov residue detected";
CM_ SG_ 1149 APP_w390_cabinCamVisDegraded "Driver assistance computer (primary): w390 cabin cam vis degraded";
CM_ SG_ 1149 APP_w391_cabinCameraBlockedonAP "Driver assistance computer (primary): w391 cabin camera blockedon AP";
CM_ SG_ 1149 APP_w392_fsdSuspended "Driver assistance computer (primary): w392 fsd suspended";
CM_ SG_ 1149 APP_w393_attnMntrUnavailable "Driver assistance computer (primary): w393 attn mntr unavailable";
CM_ SG_ 1149 APP_w394_apImuGrossErrors "Driver assistance computer (primary): w394 ap imu gross errors";
CM_ SG_ 1149 APP_w395_cabinCameraLEDFaultSvc "Driver assistance computer (primary): w395 cabin camera LED fault svc";
CM_ SG_ 1149 APP_w396_severeResidueDetected "Driver assistance computer (primary): w396 severe residue detected";
CM_ SG_ 1149 APP_w397_apFeatDisabledPermanent "Driver assistance computer (primary): w397 ap feat disabled permanent";
CM_ SG_ 1149 APP_w398_imuOutputUnhealthy "Driver assistance computer (primary): w398 imu output unhealthy";
CM_ SG_ 1149 APP_w399_brakeboosterMia "Driver assistance computer (primary): w399 brakebooster mia";
CM_ SG_ 1149 APP_w400_selfieCameraFanFault "Driver assistance computer (primary): w400 selfie camera fan fault";
CM_ SG_ 1149 APP_w401_leftPillarCameraHeaterF "Driver assistance computer (primary): w401 left pillar camera heater faulted";
CM_ SG_ 1149 APP_w402_rightPillarCameraHeater "Driver assistance computer (primary): w402 right pillar camera heater faulted";
CM_ BO_ 992 "APSB ECU message: power state inputs";
CM_ SG_ 992 APSB_A_lowPowerRequest "APSB ECU: a low power request";
CM_ SG_ 992 APSB_A_lowPowerRequestor "APSB ECU: a low power requestor";
CM_ SG_ 992 APSB_A_forcePowerOffRequest "APSB ECU: a force power off request";
CM_ SG_ 992 APSB_B_lowPowerRequest "APSB ECU: b low power request";
CM_ SG_ 992 APSB_B_lowPowerRequestor "APSB ECU: b low power requestor";
CM_ SG_ 992 APSB_B_forcePowerOffRequest "APSB ECU: b force power off request";
CM_ BO_ 1864 "APSB ECU message: state";
CM_ SG_ 1864 APSB_primaryTurbo "APSB ECU: primary turbo";
CM_ SG_ 1864 APSB_A_arbState "APSB ECU: a arb state";
CM_ SG_ 1864 APSB_A_powerState "The state of the power state machine of Turbo A.";
CM_ SG_ 1864 APSB_A_sleepState "APSB ECU: a sleep state";
CM_ SG_ 1864 APSB_A_resetState "APSB ECU: a reset state";
CM_ SG_ 1864 APSB_A_faultState "APSB ECU: a fault state";
CM_ SG_ 1864 APSB_secondaryTurbo "APSB ECU: secondary turbo";
CM_ SG_ 1864 APSB_B_arbState "APSB ECU: b arb state";
CM_ SG_ 1864 APSB_B_powerState "The state of the power state machine of Turbo B.";
CM_ SG_ 1864 APSB_B_sleepState "APSB ECU: b sleep state";
CM_ SG_ 1864 APSB_B_resetState "APSB ECU: b reset state";
CM_ SG_ 1864 APSB_B_faultState "APSB ECU: b fault state";
CM_ SG_ 1864 APSB_stateCounter "APSB ECU: state counter";
CM_ BO_ 971 "APSB ECU message: status";
CM_ SG_ 971 APSB_appStatusMonitorState "APSB ECU: app status monitor state";
CM_ SG_ 971 APSB_vehBehaviorState "APSB ECU: veh behavior state";
CM_ SG_ 971 APSB_canMaster "Indicates which of the autopilot computers is currently controlling outgoing CAN traffic; raw 3 = signal not available (SNA)";
CM_ SG_ 971 APSB_appGpioState "APSB ECU: app gpio state";
CM_ SG_ 971 APSB_eacInternalState "APSB ECU: eac internal state";
CM_ SG_ 971 APSB_switchState "APSB ECU: switch state";
CM_ SG_ 971 APSB_apbStatusMonitorState "APSB ECU: apb status monitor state";
CM_ SG_ 971 APSB_apbGpioState "APSB ECU: apb gpio state";
CM_ SG_ 971 APSB_statusCounter "APSB ECU: status counter";
CM_ SG_ 971 APSB_locLimitReason "APSB ECU: loc limit reason";
CM_ SG_ 971 APSB_appPowerStateRequest "APSB ECU: app power state request";
CM_ SG_ 971 APSB_appPowerStateReason "APSB ECU: app power state reason";
CM_ SG_ 971 APSB_apbPowerStateRequest "APSB ECU: apb power state request";
CM_ SG_ 971 APSB_apbPowerStateReason "APSB ECU: apb power state reason";
CM_ SG_ 971 APSB_heaterStateDebug "APSB ECU: heater state debug; raw 7 = signal not available (SNA)";
CM_ SG_ 971 APSB_autosummonCounter "APSB ECU: autosummon counter";
CM_ SG_ 971 APSB_autosummonAlert "APSB ECU: autosummon alert";
CM_ SG_ 971 APSB_gpsAntennaState "APSB ECU: gps antenna state";
CM_ SG_ 971 APSB_arbState "APSB ECU: arb state";
CM_ SG_ 971 APSB_socPowerOperatingMode "APSB ECU: soc power operating mode";
BA_DEF_ BO_ "GenMsgCycleTime" INT 0 3600000;
BA_DEF_ BO_ "GenMsgSendType" ENUM "Cyclic","NotUsed","NotUsed","NotUsed","NotUsed","NotUsed","NotUsed","IfActive","NoMsgSendType","NotUsed";
BA_DEF_ BO_ "VFrameFormat" ENUM "StandardCAN","ExtendedCAN","reserved","J1939PG","reserved","reserved","reserved","reserved","reserved","reserved","reserved","reserved","reserved","reserved","StandardCAN_FD","ExtendedCAN_FD";
BA_DEF_ BO_ "CANFD_BRS" ENUM "0","1";
BA_DEF_ SG_ "GenSigSNA" STRING;
BA_DEF_ SG_ "SystemSignalLongSymbol" STRING;
BA_DEF_ SG_ "Confidence" ENUM "validated","plausible","layout-only","contradicted";
BA_DEF_DEF_ "GenMsgCycleTime" 0;
BA_DEF_DEF_ "GenMsgSendType" "NoMsgSendType";
BA_DEF_DEF_ "VFrameFormat" "StandardCAN";
BA_DEF_DEF_ "CANFD_BRS" "1";
BA_DEF_DEF_ "GenSigSNA" "";
BA_DEF_DEF_ "SystemSignalLongSymbol" "";
BA_DEF_DEF_ "Confidence" "layout-only";
BA_ "GenMsgCycleTime" BO_ 809 1000;
BA_ "GenMsgSendType" BO_ 809 0;
BA_ "GenMsgCycleTime" BO_ 873 1000;
BA_ "GenMsgSendType" BO_ 873 0;
BA_ "GenMsgCycleTime" BO_ 1065 1000;
BA_ "GenMsgSendType" BO_ 1065 0;
BA_ "GenMsgCycleTime" BO_ 1081 1000;
BA_ "GenMsgSendType" BO_ 1081 0;
BA_ "GenMsgCycleTime" BO_ 1097 1000;
BA_ "GenMsgSendType" BO_ 1097 0;
BA_ "GenMsgCycleTime" BO_ 1145 1000;
BA_ "GenMsgSendType" BO_ 1145 0;
BA_ "GenMsgCycleTime" BO_ 1149 1000;
BA_ "GenMsgSendType" BO_ 1149 0;
BA_ "GenMsgCycleTime" BO_ 992 100;
BA_ "GenMsgSendType" BO_ 992 0;
BA_ "GenMsgCycleTime" BO_ 1864 100;
BA_ "GenMsgSendType" BO_ 1864 0;
BA_ "GenMsgCycleTime" BO_ 971 500;
BA_ "GenMsgSendType" BO_ 971 0;
BA_ "SystemSignalLongSymbol" SG_ 1145 APP_w349_cameraPersistentlyFault "APP_w349_cameraPersistentlyFaulted";
BA_ "SystemSignalLongSymbol" SG_ 1149 APP_w388_windshieldCameraHeaterF "APP_w388_windshieldCameraHeaterFaulted";
BA_ "SystemSignalLongSymbol" SG_ 1149 APP_w401_leftPillarCameraHeaterF "APP_w401_leftPillarCameraHeaterFaulted";
BA_ "SystemSignalLongSymbol" SG_ 1149 APP_w402_rightPillarCameraHeater "APP_w402_rightPillarCameraHeaterFaulted";
BA_ "Confidence" SG_ 992 APSB_A_lowPowerRequest 0;
BA_ "Confidence" SG_ 992 APSB_A_lowPowerRequestor 0;
BA_ "Confidence" SG_ 992 APSB_A_forcePowerOffRequest 0;
BA_ "Confidence" SG_ 992 APSB_B_lowPowerRequest 0;
BA_ "Confidence" SG_ 992 APSB_B_lowPowerRequestor 0;
BA_ "Confidence" SG_ 992 APSB_B_forcePowerOffRequest 0;
BA_ "Confidence" SG_ 1864 APSB_primaryTurbo 0;
BA_ "Confidence" SG_ 1864 APSB_A_arbState 0;
BA_ "Confidence" SG_ 1864 APSB_A_powerState 0;
BA_ "Confidence" SG_ 1864 APSB_A_sleepState 0;
BA_ "Confidence" SG_ 1864 APSB_A_resetState 0;
BA_ "Confidence" SG_ 1864 APSB_A_faultState 0;
BA_ "Confidence" SG_ 1864 APSB_secondaryTurbo 0;
BA_ "Confidence" SG_ 1864 APSB_B_arbState 0;
BA_ "Confidence" SG_ 1864 APSB_B_powerState 0;
BA_ "Confidence" SG_ 1864 APSB_B_sleepState 0;
BA_ "Confidence" SG_ 1864 APSB_B_resetState 0;
BA_ "Confidence" SG_ 1864 APSB_B_faultState 0;
BA_ "Confidence" SG_ 971 APSB_appStatusMonitorState 0;
BA_ "Confidence" SG_ 971 APSB_vehBehaviorState 0;
BA_ "Confidence" SG_ 971 APSB_canMaster 0;
BA_ "GenSigSNA" SG_ 971 APSB_canMaster "3";
BA_ "Confidence" SG_ 971 APSB_appGpioState 0;
BA_ "Confidence" SG_ 971 APSB_eacInternalState 0;
BA_ "Confidence" SG_ 971 APSB_switchState 0;
BA_ "Confidence" SG_ 971 APSB_apbStatusMonitorState 0;
BA_ "Confidence" SG_ 971 APSB_apbGpioState 0;
BA_ "Confidence" SG_ 971 APSB_statusCounter 0;
BA_ "Confidence" SG_ 971 APSB_locLimitReason 0;
BA_ "Confidence" SG_ 971 APSB_appPowerStateRequest 0;
BA_ "Confidence" SG_ 971 APSB_appPowerStateReason 0;
BA_ "Confidence" SG_ 971 APSB_apbPowerStateRequest 0;
BA_ "Confidence" SG_ 971 APSB_apbPowerStateReason 0;
BA_ "Confidence" SG_ 971 APSB_heaterStateDebug 0;
BA_ "GenSigSNA" SG_ 971 APSB_heaterStateDebug "7";
BA_ "Confidence" SG_ 971 APSB_autosummonCounter 0;
BA_ "Confidence" SG_ 971 APSB_autosummonAlert 0;
BA_ "Confidence" SG_ 971 APSB_gpsAntennaState 0;
BA_ "Confidence" SG_ 971 APSB_arbState 0;
BA_ "Confidence" SG_ 971 APSB_socPowerOperatingMode 0;
VAL_ 992 APSB_A_lowPowerRequest 5 "APS_LOW_POWER_COLD_RESET" 4 "APS_LOW_POWER_SOC_WARM_RESET" 3 "APS_LOW_POWER_AP_WARM_RESET" 2 "APS_LOW_POWER_OFF" 1 "APS_LOW_POWER_SUSPEND" 0 "APS_LOW_POWER_NONE" ;
VAL_ 992 APSB_A_lowPowerRequestor 10 "APS_LOW_POWER_REQ_COUNT" 9 "APS_LOW_POWER_REQ_SGK_PGOOD_IRQ" 8 "APS_LOW_POWER_REQ_SGK_CONSOLE" 7 "APS_LOW_POWER_REQ_SGK_SLEEP" 6 "APS_LOW_POWER_REQ_SGK_UDS" 5 "APS_LOW_POWER_REQ_SGK_BRIDGE" 4 "APS_LOW_POWER_REQ_SGK_FM" 3 "APS_LOW_POWER_REQ_SGK_POWER" 2 "APS_LOW_POWER_REQ_AP_MAILBOX" 1 "APS_LOW_POWER_REQ_AP_ATF" 0 "APS_LOW_POWER_REQ_NONE" ;
VAL_ 992 APSB_B_lowPowerRequest 5 "APS_LOW_POWER_COLD_RESET" 4 "APS_LOW_POWER_SOC_WARM_RESET" 3 "APS_LOW_POWER_AP_WARM_RESET" 2 "APS_LOW_POWER_OFF" 1 "APS_LOW_POWER_SUSPEND" 0 "APS_LOW_POWER_NONE" ;
VAL_ 992 APSB_B_lowPowerRequestor 10 "APS_LOW_POWER_REQ_COUNT" 9 "APS_LOW_POWER_REQ_SGK_PGOOD_IRQ" 8 "APS_LOW_POWER_REQ_SGK_CONSOLE" 7 "APS_LOW_POWER_REQ_SGK_SLEEP" 6 "APS_LOW_POWER_REQ_SGK_UDS" 5 "APS_LOW_POWER_REQ_SGK_BRIDGE" 4 "APS_LOW_POWER_REQ_SGK_FM" 3 "APS_LOW_POWER_REQ_SGK_POWER" 2 "APS_LOW_POWER_REQ_AP_MAILBOX" 1 "APS_LOW_POWER_REQ_AP_ATF" 0 "APS_LOW_POWER_REQ_NONE" ;
VAL_ 1864 APSB_primaryTurbo 2 "TURBO_UNKNOWN" 1 "TURBO_B" 0 "TURBO_A" ;
VAL_ 1864 APSB_A_arbState 7 "ARB_STATE_COUNT" 6 "ARB_STATE_UNKNOWN" 5 "ARB_STATE_MIA" 4 "ARB_STATE_FAULT" 3 "ARB_STATE_SECONDARY" 2 "ARB_STATE_PRIMARY" 1 "ARB_STATE_IDLE" 0 "ARB_STATE_INIT" ;
VAL_ 1864 APSB_A_powerState 28 "POWER_STATE_AP_FORCE_POWER_OFF" 27 "POWER_STATE_AP_WAIT_FOR_SHUTDOWN_ABORT" 26 "POWER_STATE_AP_IN_LINUX" 25 "POWER_STATE_AP_IDLE" 24 "POWER_STATE_VEH_BOOTING" 23 "POWER_STATE_UNKNOWN" 22 "POWER_STATE_MIA" 21 "POWER_STATE_FAULT" 20 "POWER_STATE_SOC_OFF_ABORT" 19 "POWER_STATE_SOC_OFF" 18 "POWER_STATE_SOC_OFF_READY" 17 "POWER_STATE_AP_SUSPENDED" 16 "POWER_STATE_AP_OFF_ABORT_WAIT_FOR_ACK" 15 "POWER_STATE_AP_OFF_ABORT" 14 "POWER_STATE_AP_OFF_READY_WAIT_FOR_RESPONSE" 13 "POWER_STATE_AP_OFF_READY_WAIT_FOR_ACK" 12 "POWER_STATE_AP_OFF_READY" 11 "POWER_STATE_AP_OFF_PREPARE" 10 "POWER_STATE_AP_WAIT_FOR_SHUTDOWN" 9 "POWER_STATE_AP_ON" 8 "POWER_STATE_AP_IN_COREBOOT" 7 "POWER_STATE_AP_BOOTING" 6 "POWER_STATE_AP_ON_READY_WAIT_FOR_RESPONSE" 5 "POWER_STATE_AP_ON_READY_WAIT_FOR_ACK" 4 "POWER_STATE_AP_ON_READY" 3 "POWER_STATE_AP_ON_PREPARE_WAIT_FOR_RESPONSE" 2 "POWER_STATE_AP_ON_PREPARE_WAIT_FOR_ACK" 1 "POWER_STATE_AP_ON_PREPARE" 0 "POWER_STATE_IDLE" ;
VAL_ 1864 APSB_A_sleepState 9 "SLEEP_STATE_COUNT" 8 "SLEEP_STATE_UNKNOWN" 7 "SLEEP_STATE_MIA" 6 "SLEEP_STATE_FAULT" 5 "SLEEP_STATE_ABORT" 4 "SLEEP_STATE_SLEEPING" 3 "SLEEP_STATE_GOING_TO_SLEEP" 2 "SLEEP_STATE_READY" 1 "SLEEP_STATE_WAIT_FOR_BUS_SILENCE" 0 "SLEEP_STATE_IDLE" ;
VAL_ 1864 APSB_A_resetState 5 "RESET_STATE_COUNT" 4 "RESET_STATE_UNKNOWN" 3 "RESET_STATE_MIA" 2 "RESET_STATE_FAULT" 1 "RESET_STATE_RESETTING" 0 "RESET_STATE_NOT_RESETTING" ;
VAL_ 1864 APSB_A_faultState 27 "FAULT_STATE_COUNT" 26 "FAULT_STATE_UNKNOWN" 25 "FAULT_STATE_MIA" 24 "FAULT_STATE_UNEXPECTED" 23 "FAULT_STATE_SCS" 22 "FAULT_STATE_SOFTWARE_FAULT" 21 "FAULT_STATE_TRIP1_FAULT" 20 "FAULT_STATE_TRIP0_FAULT" 19 "FAULT_STATE_WDT" 18 "FAULT_STATE_CPU_FAULT" 17 "FAULT_STATE_DROOP_TRIP" 16 "FAULT_STATE_DROOP_GPU" 15 "FAULT_STATE_DROOP_CPUCL2" 14 "FAULT_STATE_DROOP_CPUCL1" 13 "FAULT_STATE_DROOP_CPUCL0" 12 "FAULT_STATE_MIF_ECC_AP" 11 "FAULT_STATE_MIF7_DFI_ALERT" 10 "FAULT_STATE_MIF6_DFI_ALERT" 9 "FAULT_STATE_MIF5_DFI_ALERT" 8 "FAULT_STATE_MIF4_DFI_ALERT" 7 "FAULT_STATE_MIF3_DFI_ALERT" 6 "FAULT_STATE_MIF2_DFI_ALERT" 5 "FAULT_STATE_MIF1_DFI_ALERT" 4 "FAULT_STATE_MIF0_DFI_ALERT" 3 "FAULT_STATE_MIF_ECC_UNCORRECTED" 2 "FAULT_STATE_MIF_ECC_CORRECTED" 1 "FAULT_STATE_GIC" 0 "FAULT_STATE_NONE" ;
VAL_ 1864 APSB_secondaryTurbo 2 "TURBO_UNKNOWN" 1 "TURBO_B" 0 "TURBO_A" ;
VAL_ 1864 APSB_B_arbState 7 "ARB_STATE_COUNT" 6 "ARB_STATE_UNKNOWN" 5 "ARB_STATE_MIA" 4 "ARB_STATE_FAULT" 3 "ARB_STATE_SECONDARY" 2 "ARB_STATE_PRIMARY" 1 "ARB_STATE_IDLE" 0 "ARB_STATE_INIT" ;
VAL_ 1864 APSB_B_powerState 28 "POWER_STATE_AP_FORCE_POWER_OFF" 27 "POWER_STATE_AP_WAIT_FOR_SHUTDOWN_ABORT" 26 "POWER_STATE_AP_IN_LINUX" 25 "POWER_STATE_AP_IDLE" 24 "POWER_STATE_VEH_BOOTING" 23 "POWER_STATE_UNKNOWN" 22 "POWER_STATE_MIA" 21 "POWER_STATE_FAULT" 20 "POWER_STATE_SOC_OFF_ABORT" 19 "POWER_STATE_SOC_OFF" 18 "POWER_STATE_SOC_OFF_READY" 17 "POWER_STATE_AP_SUSPENDED" 16 "POWER_STATE_AP_OFF_ABORT_WAIT_FOR_ACK" 15 "POWER_STATE_AP_OFF_ABORT" 14 "POWER_STATE_AP_OFF_READY_WAIT_FOR_RESPONSE" 13 "POWER_STATE_AP_OFF_READY_WAIT_FOR_ACK" 12 "POWER_STATE_AP_OFF_READY" 11 "POWER_STATE_AP_OFF_PREPARE" 10 "POWER_STATE_AP_WAIT_FOR_SHUTDOWN" 9 "POWER_STATE_AP_ON" 8 "POWER_STATE_AP_IN_COREBOOT" 7 "POWER_STATE_AP_BOOTING" 6 "POWER_STATE_AP_ON_READY_WAIT_FOR_RESPONSE" 5 "POWER_STATE_AP_ON_READY_WAIT_FOR_ACK" 4 "POWER_STATE_AP_ON_READY" 3 "POWER_STATE_AP_ON_PREPARE_WAIT_FOR_RESPONSE" 2 "POWER_STATE_AP_ON_PREPARE_WAIT_FOR_ACK" 1 "POWER_STATE_AP_ON_PREPARE" 0 "POWER_STATE_IDLE" ;
VAL_ 1864 APSB_B_sleepState 9 "SLEEP_STATE_COUNT" 8 "SLEEP_STATE_UNKNOWN" 7 "SLEEP_STATE_MIA" 6 "SLEEP_STATE_FAULT" 5 "SLEEP_STATE_ABORT" 4 "SLEEP_STATE_SLEEPING" 3 "SLEEP_STATE_GOING_TO_SLEEP" 2 "SLEEP_STATE_READY" 1 "SLEEP_STATE_WAIT_FOR_BUS_SILENCE" 0 "SLEEP_STATE_IDLE" ;
VAL_ 1864 APSB_B_resetState 5 "RESET_STATE_COUNT" 4 "RESET_STATE_UNKNOWN" 3 "RESET_STATE_MIA" 2 "RESET_STATE_FAULT" 1 "RESET_STATE_RESETTING" 0 "RESET_STATE_NOT_RESETTING" ;
VAL_ 1864 APSB_B_faultState 27 "FAULT_STATE_COUNT" 26 "FAULT_STATE_UNKNOWN" 25 "FAULT_STATE_MIA" 24 "FAULT_STATE_UNEXPECTED" 23 "FAULT_STATE_SCS" 22 "FAULT_STATE_SOFTWARE_FAULT" 21 "FAULT_STATE_TRIP1_FAULT" 20 "FAULT_STATE_TRIP0_FAULT" 19 "FAULT_STATE_WDT" 18 "FAULT_STATE_CPU_FAULT" 17 "FAULT_STATE_DROOP_TRIP" 16 "FAULT_STATE_DROOP_GPU" 15 "FAULT_STATE_DROOP_CPUCL2" 14 "FAULT_STATE_DROOP_CPUCL1" 13 "FAULT_STATE_DROOP_CPUCL0" 12 "FAULT_STATE_MIF_ECC_AP" 11 "FAULT_STATE_MIF7_DFI_ALERT" 10 "FAULT_STATE_MIF6_DFI_ALERT" 9 "FAULT_STATE_MIF5_DFI_ALERT" 8 "FAULT_STATE_MIF4_DFI_ALERT" 7 "FAULT_STATE_MIF3_DFI_ALERT" 6 "FAULT_STATE_MIF2_DFI_ALERT" 5 "FAULT_STATE_MIF1_DFI_ALERT" 4 "FAULT_STATE_MIF0_DFI_ALERT" 3 "FAULT_STATE_MIF_ECC_UNCORRECTED" 2 "FAULT_STATE_MIF_ECC_CORRECTED" 1 "FAULT_STATE_GIC" 0 "FAULT_STATE_NONE" ;
VAL_ 971 APSB_appStatusMonitorState 7 "STATUS_MONITOR_NUM_STATES" 6 "STATUS_MONITOR_STATE_RECOVERY" 5 "STATUS_MONITOR_STATE_SHUTTING_DOWN" 4 "STATUS_MONITOR_STATE_CRITICAL" 3 "STATUS_MONITOR_STATE_NOMINAL" 2 "STATUS_MONITOR_STATE_INIT" 1 "STATUS_MONITOR_STATE_PWR_OFF" 0 "STATUS_MONITOR_STATE_UNKNOWN" ;
VAL_ 971 APSB_vehBehaviorState 8 "VEH_BEHAVIOR_NUM_STATES" 7 "VEH_BEHAVIOR_STATE_SYSTEM_FAULT" 6 "VEH_BEHAVIOR_STATE_APS_OVERRIDE" 5 "VEH_BEHAVIOR_STATE_APS_FAIL_SAFE" 4 "VEH_BEHAVIOR_STATE_APS_BRIDGE_APB" 3 "VEH_BEHAVIOR_STATE_APS_BRIDGE_APP" 2 "VEH_BEHAVIOR_STATE_APS_CONTROL" 1 "VEH_BEHAVIOR_STATE_APS_AVAILABLE" 0 "VEH_BEHAVIOR_STATE_UNKNOWN" ;
VAL_ 971 APSB_canMaster 3 "CAN_MASTER_SNA" 2 "CAN_MASTER_APB" 1 "CAN_MASTER_APP" 0 "CAN_MASTER_APS" ;
VAL_ 971 APSB_appGpioState 3 "AP_GPIO_STATE_HEALTHY" 2 "AP_GPIO_STATE_CRITICAL" 1 "AP_GPIO_STATE_DISABLED" 0 "AP_GPIO_STATE_PWR_DOWN_REBOOT" ;
VAL_ 971 APSB_eacInternalState 7 "APS_EAC_NUM_STATES" 6 "APS_EAC_STATE_LSS" 5 "APS_EAC_STATE_OVERRIDE" 4 "APS_EAC_STATE_INHIBIT" 3 "APS_EAC_STATE_AUTOPARK" 2 "APS_EAC_STATE_CONTINUOUS" 1 "APS_EAC_STATE_MOMENTARY" 0 "APS_EAC_STATE_INIT" ;
VAL_ 971 APSB_apbStatusMonitorState 7 "STATUS_MONITOR_NUM_STATES" 6 "STATUS_MONITOR_STATE_RECOVERY" 5 "STATUS_MONITOR_STATE_SHUTTING_DOWN" 4 "STATUS_MONITOR_STATE_CRITICAL" 3 "STATUS_MONITOR_STATE_NOMINAL" 2 "STATUS_MONITOR_STATE_INIT" 1 "STATUS_MONITOR_STATE_PWR_OFF" 0 "STATUS_MONITOR_STATE_UNKNOWN" ;
VAL_ 971 APSB_apbGpioState 3 "AP_GPIO_STATE_HEALTHY" 2 "AP_GPIO_STATE_CRITICAL" 1 "AP_GPIO_STATE_DISABLED" 0 "AP_GPIO_STATE_PWR_DOWN_REBOOT" ;
VAL_ 971 APSB_locLimitReason 7 "LOC_LIMITS_EXTENDED" 6 "LOC_MONITOR_UNAVAILABLE" 5 "NO_RADAR_TARGET" 4 "RADAR_NOT_HEALTHY" 3 "PRIMARY_AP_NOT_HEALTHY" 2 "ACC_AND_AEB_UNAVAILABLE" 1 "NOT_IN_DRIVE" 0 "NOMINAL_DEFAULT" ;
VAL_ 971 APSB_appPowerStateRequest 3 "AP_POWER_STATE_SLEEP" 2 "AP_POWER_STATE_SUSPEND" 1 "AP_POWER_STATE_SENTRY" 0 "AP_POWER_STATE_NOMINAL" ;
VAL_ 971 APSB_appPowerStateReason 12 "UI_SUMMON_STANDBY_MODE_ENABLED" 11 "SLEEP_REQUEST_RECVD" 10 "AP_POWER_REQUEST_OVERHEATED" 9 "LOADSHED_POWER_REQUEST_PENDING" 8 "VC_POWER_REQUEST" 7 "AP_POWER_REQUEST_OVERRIDE" 6 "AP_POWER_REQUEST_OVERHEATING" 5 "AP_POWER_REQUEST_HYSTERESIS" 4 "GTW_GOTO_FULL_POWER" 3 "AP_NOT_IN_PARK" 2 "AP_NM_REASON_SET" 1 "AP_WDOG_UNHEALTHY" 0 "UI_POWER_STATE_REQUEST" ;
VAL_ 971 APSB_apbPowerStateRequest 3 "AP_POWER_STATE_SLEEP" 2 "AP_POWER_STATE_SUSPEND" 1 "AP_POWER_STATE_SENTRY" 0 "AP_POWER_STATE_NOMINAL" ;
VAL_ 971 APSB_apbPowerStateReason 12 "UI_SUMMON_STANDBY_MODE_ENABLED" 11 "SLEEP_REQUEST_RECVD" 10 "AP_POWER_REQUEST_OVERHEATED" 9 "LOADSHED_POWER_REQUEST_PENDING" 8 "VC_POWER_REQUEST" 7 "AP_POWER_REQUEST_OVERRIDE" 6 "AP_POWER_REQUEST_OVERHEATING" 5 "AP_POWER_REQUEST_HYSTERESIS" 4 "GTW_GOTO_FULL_POWER" 3 "AP_NOT_IN_PARK" 2 "AP_NM_REASON_SET" 1 "AP_WDOG_UNHEALTHY" 0 "UI_POWER_STATE_REQUEST" ;
VAL_ 971 APSB_heaterStateDebug 7 "APS_HEATER_SNA" 4 "APS_HEATER_FAULT_SHORT" 3 "APS_HEATER_FAULT_OPEN" 2 "APS_HEATER_ON_NOT_HEATING" 1 "APS_HEATER_ON_HEATING" 0 "APS_HEATER_OFF" ;
VAL_ 971 APSB_gpsAntennaState 2 "GPS_ANTENNA_CONNECTED" 1 "GPS_ANTENNA_UNKNOWN" 0 "GPS_ANTENNA_DISCONNECTED" ;
VAL_ 971 APSB_arbState 7 "ARB_STATE_N_COUNT" 6 "ARB_STATE_N_UNKNOWN" 5 "ARB_STATE_N_MIA" 4 "ARB_STATE_N_FAULT" 3 "ARB_STATE_N_SECONDARY" 2 "ARB_STATE_N_PRIMARY" 1 "ARB_STATE_N_IDLE" 0 "ARB_STATE_N_INIT" ;
VAL_ 971 APSB_socPowerOperatingMode 2 "APS_DUAL_SOC" 1 "APS_SINGLE_SOC" 0 "APS_UNKNOWN" ;
